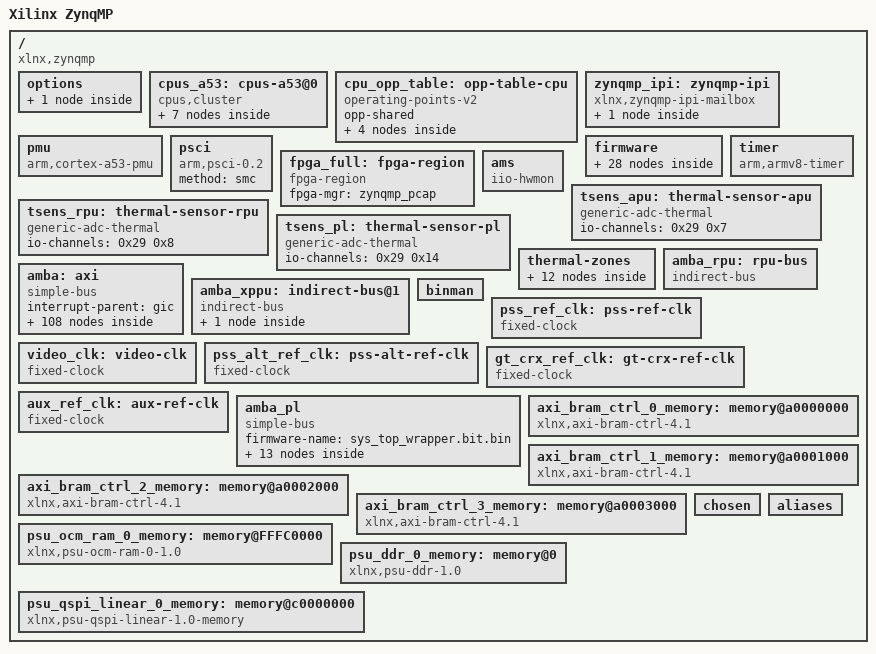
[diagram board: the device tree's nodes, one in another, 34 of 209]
/dts-v1/;
/ {
        compatible = "xlnx,zynqmp";
        #address-cells = <0x2>;
        #size-cells = <0x2>;
        model = "Xilinx ZynqMP";
        device_id = "xczu17eg";
        slrcount = <0x1>;
        family = "ZynqMP";
        speed_grade = "2";
        pruned-sdt = <0x1>;

        options {

                u-boot {
                        compatible = "u-boot,config";
                        bootscr-address = <0x0 0x20000000>;
                };
        };

        cpus_a53: cpus-a53@0 {
                #address-cells = <0x1>;
                #size-cells = <0x0>;
                compatible = "cpus,cluster";
                address-map = <0x0 0xf0000000 &amba 0x0 0xf0000000 0x0 0x10000000>,
                 <0x0 0x0 &zynqmp_reset 0x0 0x0 0x0 0x0>,
                 <0x0 0x0 &pinctrl0 0x0 0x0 0x0 0x0>,
                 <0x0 0xffa50800 &ams_ps 0x0 0xffa50800 0x0 0x400>,
                 <0x0 0xffa50c00 &ams_pl 0x0 0xffa50c00 0x0 0x400>,
                 <0x0 0xa0000000 &axi_bram_ctrl_0_memory 0x0 0xa0000000 0x0 0x1000>,
                 <0x0 0xa0000000 &axi_bram_ctrl_0 0x0 0xa0000000 0x0 0x1000>,
                 <0x0 0xa0001000 &axi_bram_ctrl_1_memory 0x0 0xa0001000 0x0 0x1000>,
                 <0x0 0xa0001000 &axi_bram_ctrl_1 0x0 0xa0001000 0x0 0x1000>,
                 <0x0 0xa0002000 &axi_bram_ctrl_2_memory 0x0 0xa0002000 0x0 0x1000>,
                 <0x0 0xa0002000 &axi_bram_ctrl_2 0x0 0xa0002000 0x0 0x1000>,
                 <0x0 0xa0003000 &axi_bram_ctrl_3_memory 0x0 0xa0003000 0x0 0x1000>,
                 <0x0 0xa0003000 &axi_bram_ctrl_3 0x0 0xa0003000 0x0 0x1000>,
                 <0x0 0xfffc0000 &psu_ocm_ram_0_memory 0x0 0xfffc0000 0x0 0x40000>,
                 <0x0 0xff300000 &ipi0 0x0 0xff300000 0x0 0x10000>,
                 <0x0 0x0 &psu_ddr_0_memory 0x0 0x0 0x0 0x7ff00000>,
                 <0x0 0xa0010000 &t4nfc_hlper_0 0x0 0xa0010000 0x0 0x10000>,
                 <0x0 0xa0020000 &t4nfc_hlper_1 0x0 0xa0020000 0x0 0x10000>,
                 <0x0 0xa0030000 &t4nfc_hlper_2 0x0 0xa0030000 0x0 0x10000>,
                 <0x0 0xa0040000 &t4nfc_hlper_3 0x0 0xa0040000 0x0 0x10000>,
                 <0x0 0xb0000000 &iodelay_if_0 0x0 0xb0000000 0x0 0x10000>,
                 <0x0 0xb0010000 &iodelay_if_0_dqs 0x0 0xb0010000 0x0 0x10000>,
                 <0x0 0xb0020000 &nvme_ctrl_0 0x0 0xb0020000 0x0 0x20000>,
                 <0x0 0xf9010000 &gic 0x0 0xf9010000 0x0 0x70000>,
                 <0x0 0xffa80000 &lpd_dma_chan1 0x0 0xffa80000 0x0 0x10000>,
                 <0x0 0xffa90000 &lpd_dma_chan2 0x0 0xffa90000 0x0 0x10000>,
                 <0x0 0xffaa0000 &lpd_dma_chan3 0x0 0xffaa0000 0x0 0x10000>,
                 <0x0 0xffab0000 &lpd_dma_chan4 0x0 0xffab0000 0x0 0x10000>,
                 <0x0 0xffac0000 &lpd_dma_chan5 0x0 0xffac0000 0x0 0x10000>,
                 <0x0 0xffad0000 &lpd_dma_chan6 0x0 0xffad0000 0x0 0x10000>,
                 <0x0 0xffae0000 &lpd_dma_chan7 0x0 0xffae0000 0x0 0x10000>,
                 <0x0 0xffaf0000 &lpd_dma_chan8 0x0 0xffaf0000 0x0 0x10000>,
                 <0x0 0xfd360000 &psu_afi_0 0x0 0xfd360000 0x0 0x10000>,
                 <0x0 0xfd370000 &psu_afi_1 0x0 0xfd370000 0x0 0x10000>,
                 <0x0 0xfd380000 &psu_afi_2 0x0 0xfd380000 0x0 0x10000>,
                 <0x0 0xfd390000 &psu_afi_3 0x0 0xfd390000 0x0 0x10000>,
                 <0x0 0xfd3a0000 &psu_afi_4 0x0 0xfd3a0000 0x0 0x10000>,
                 <0x0 0xfd3b0000 &psu_afi_5 0x0 0xfd3b0000 0x0 0x10000>,
                 <0x0 0xff9b0000 &psu_afi_6 0x0 0xff9b0000 0x0 0x10000>,
                 <0x0 0xffa50000 &xilinx_ams 0x0 0xffa50000 0x0 0x10000>,
                 <0x0 0xfd0b0000 &perf_monitor_ddr 0x0 0xfd0b0000 0x0 0x10000>,
                 <0x0 0xffa00000 &perf_monitor_ocm 0x0 0xffa00000 0x0 0x10000>,
                 <0x0 0xffa10000 &perf_monitor_lpd 0x0 0xffa10000 0x0 0x10000>,
                 <0x0 0xfd490000 &perf_monitor_cci 0x0 0xfd490000 0x0 0x10000>,
                 <0x0 0xfd5c0000 &psu_apu 0x0 0xfd5c0000 0x0 0x10000>,
                 <0x0 0xfd6e0000 &psu_cci_gpv 0x0 0xfd6e0000 0x0 0x10000>,
                 <0x0 0xfd5e0000 &psu_cci_reg 0x0 0xfd5e0000 0x0 0x10000>,
                 <0x0 0xfe800000 &coresight_0 0x0 0xfe800000 0x0 0x800000>,
                 <0x0 0xfd1a0000 &psu_crf_apb 0x0 0xfd1a0000 0x0 0x140000>,
                 <0x0 0xff5e0000 &psu_crl_apb 0x0 0xff5e0000 0x0 0x280000>,
                 <0x0 0xffca0000 &psu_csu_0 0x0 0xffca0000 0x0 0x10000>,
                 <0x0 0xffc80000 &csudma_0 0x0 0xffc80000 0x0 0x20000>,
                 <0x0 0xff380000 &psu_ctrl_ipi 0x0 0xff380000 0x0 0x80000>,
                 <0x0 0xfd080000 &psu_ddr_phy 0x0 0xfd080000 0x0 0x10000>,
                 <0x0 0xfd090000 &psu_ddr_qos_ctrl 0x0 0xfd090000 0x0 0x10000>,
                 <0x0 0xfd000000 &psu_ddr_xmpu0_cfg 0x0 0xfd000000 0x0 0x10000>,
                 <0x0 0xfd010000 &psu_ddr_xmpu1_cfg 0x0 0xfd010000 0x0 0x10000>,
                 <0x0 0xfd020000 &psu_ddr_xmpu2_cfg 0x0 0xfd020000 0x0 0x10000>,
                 <0x0 0xfd030000 &psu_ddr_xmpu3_cfg 0x0 0xfd030000 0x0 0x10000>,
                 <0x0 0xfd040000 &psu_ddr_xmpu4_cfg 0x0 0xfd040000 0x0 0x10000>,
                 <0x0 0xfd050000 &psu_ddr_xmpu5_cfg 0x0 0xfd050000 0x0 0x10000>,
                 <0x0 0xfd070000 &mc 0x0 0xfd070000 0x0 0x1000>,
                 <0x0 0xffcc0000 &psu_efuse 0x0 0xffcc0000 0x0 0x10000>,
                 <0x0 0xff0e0000 &gem3 0x0 0xff0e0000 0x0 0x10000>,
                 <0x0 0xfd700000 &psu_fpd_gpv 0x0 0xfd700000 0x0 0x100000>,
                 <0x0 0xfd610000 &psu_fpd_slcr 0x0 0xfd610000 0x0 0x80000>,
                 <0x0 0xfd690000 &psu_fpd_slcr_secure 0x0 0xfd690000 0x0 0x40000>,
                 <0x0 0xfd5d0000 &psu_fpd_xmpu_cfg 0x0 0xfd5d0000 0x0 0x10000>,
                 <0x0 0xfd4f0000 &psu_fpd_xmpu_sink 0x0 0xfd4f0000 0x0 0x10000>,
                 <0x0 0xfd500000 &fpd_dma_chan1 0x0 0xfd500000 0x0 0x10000>,
                 <0x0 0xfd510000 &fpd_dma_chan2 0x0 0xfd510000 0x0 0x10000>,
                 <0x0 0xfd520000 &fpd_dma_chan3 0x0 0xfd520000 0x0 0x10000>,
                 <0x0 0xfd530000 &fpd_dma_chan4 0x0 0xfd530000 0x0 0x10000>,
                 <0x0 0xfd540000 &fpd_dma_chan5 0x0 0xfd540000 0x0 0x10000>,
                 <0x0 0xfd550000 &fpd_dma_chan6 0x0 0xfd550000 0x0 0x10000>,
                 <0x0 0xfd560000 &fpd_dma_chan7 0x0 0xfd560000 0x0 0x10000>,
                 <0x0 0xfd570000 &fpd_dma_chan8 0x0 0xfd570000 0x0 0x10000>,
                 <0x0 0xff0a0000 &gpio 0x0 0xff0a0000 0x0 0x10000>,
                 <0x0 0xfd4b0000 &gpu 0x0 0xfd4b0000 0x0 0x10000>,
                 <0x0 0xff020000 &i2c0 0x0 0xff020000 0x0 0x10000>,
                 <0x0 0xff030000 &i2c1 0x0 0xff030000 0x0 0x10000>,
                 <0x0 0xff250000 &psu_iou_scntr 0x0 0xff250000 0x0 0x10000>,
                 <0x0 0xff260000 &psu_iou_scntrs 0x0 0xff260000 0x0 0x10000>,
                 <0x0 0xff240000 &psu_iousecure_slcr 0x0 0xff240000 0x0 0x10000>,
                 <0x0 0xff180000 &psu_iouslcr_0 0x0 0xff180000 0x0 0xc0000>,
                 <0x0 0xff410000 &psu_lpd_slcr 0x0 0xff410000 0x0 0xa0000>,
                 <0x0 0xff4b0000 &psu_lpd_slcr_secure 0x0 0xff4b0000 0x0 0x30000>,
                 <0x0 0xff980000 &lpd_xppu 0x0 0xff980000 0x0 0x10000>,
                 <0x0 0xff9c0000 &psu_lpd_xppu_sink 0x0 0xff9c0000 0x0 0x10000>,
                 <0x0 0xffcf0000 &psu_mbistjtag 0x0 0xffcf0000 0x0 0x10000>,
                 <0x0 0xff990000 &psu_message_buffers 0x0 0xff990000 0x0 0x10000>,
                 <0x0 0xff960000 &ocm 0x0 0xff960000 0x0 0x10000>,
                 <0x0 0xffa70000 &psu_ocm_xmpu_cfg 0x0 0xffa70000 0x0 0x10000>,
                 <0x0 0xffd80000 &psu_pmu_global_0 0x0 0xffd80000 0x0 0x40000>,
                 <0x0 0xff0f0000 &qspi 0x0 0xff0f0000 0x0 0x10000>,
                 <0x0 0xc0000000 &psu_qspi_linear_0_memory 0x0 0xc0000000 0x0 0x20000000>,
                 <0x0 0xffe00000 &psu_r5_0_atcm_global 0x0 0xffe00000 0x0 0x10000>,
                 <0x0 0xffe20000 &psu_r5_0_btcm_global 0x0 0xffe20000 0x0 0x10000>,
                 <0x0 0xffe90000 &psu_r5_1_atcm_global 0x0 0xffe90000 0x0 0x10000>,
                 <0x0 0xffeb0000 &psu_r5_1_btcm_global 0x0 0xffeb0000 0x0 0x10000>,
                 <0x0 0xffe00000 &psu_r5_tcm_ram_global 0x0 0xffe00000 0x0 0x40000>,
                 <0x0 0xff9a0000 &psu_rpu 0x0 0xff9a0000 0x0 0x10000>,
                 <0x0 0xffce0000 &psu_rsa 0x0 0xffce0000 0x0 0x10000>,
                 <0x0 0xffa60000 &rtc 0x0 0xffa60000 0x0 0x10000>,
                 <0x0 0xff170000 &sdhci1 0x0 0xff170000 0x0 0x10000>,
                 <0x0 0xfd400000 &psgtr 0x0 0xfd400000 0x0 0x80000>,
                 <0x0 0xfd3d0000 &psu_siou 0x0 0xfd3d0000 0x0 0x10000>,
                 <0x0 0xfd800000 &smmu 0x0 0xfd800000 0x0 0x800000>,
                 <0x0 0xfd5f0000 &psu_smmu_reg 0x0 0xfd5f0000 0x0 0x10000>,
                 <0x0 0xff000000 &uart0 0x0 0xff000000 0x0 0x10000>,
                 <0x0 0xff010000 &uart1 0x0 0xff010000 0x0 0x10000>;
                #ranges-address-cells = <0x2>;
                #ranges-size-cells = <0x2>;
                phandle = <0x9d>;

                psu_cortexa53_0: cpu@0 {
                        #cooling-cells = <0x2>;
                        compatible = "arm,cortex-a53";
                        device_type = "cpu";
                        enable-method = "psci";
                        operating-points-v2 = <&cpu_opp_table>;
                        reg = <0x0>;
                        cpu-idle-states = <&CPU_SLEEP_0>;
                        next-level-cache = <&L2>;
                        clocks = <&zynqmp_clk 0xa>;
                        xlnx,psu-ep = <0x1>;
                        xlnx,pss-video-ref-clk-freq = <0x1fc9f08>;
                        xlnx,ip-name = "psu_cortexa53";
                        xlnx,cpu-1x-clk-freq-hz = <0x0>;
                        xlnx,psu-silicon-version = <0x3>;
                        cpu-frequency = <0x4f78d984>;
                        xlnx,cpu-clk-freq-hz = <0x4f78d984>;
                        xlnx,pss-gt-ref-clk-freq = <0x1fc9f08>;
                        xlnx,pss-ref-clk-freq = <0x1fc9f08>;
                        bus-handle = <0x1>;
                        xlnx,pss-aux-ref-clk-freq = <0x1fc9f08>;
                        xlnx,psu-device = "PS8a";
                        xlnx,timestamp-clk-freq = <0x1fc9f08>;
                        stamp-frequency = <0x1fc9f08>;
                        xlnx,pss-alt-ref-clk-freq = <0x1fc9f08>;
                        phandle = <0x88>;
                };

                psu_cortexa53_1: cpu@1 {
                        #cooling-cells = <0x2>;
                        compatible = "arm,cortex-a53";
                        device_type = "cpu";
                        enable-method = "psci";
                        reg = <0x1>;
                        operating-points-v2 = <&cpu_opp_table>;
                        cpu-idle-states = <&CPU_SLEEP_0>;
                        next-level-cache = <&L2>;
                        xlnx,timestamp-clk-freq = <0x1fc9f08>;
                        xlnx,psu-ep = <0x1>;
                        xlnx,pss-ref-clk-freq = <0x1fc9f08>;
                        stamp-frequency = <0x1fc9f08>;
                        xlnx,cpu-1x-clk-freq-hz = <0x0>;
                        xlnx,ip-name = "psu_cortexa53";
                        xlnx,psu-silicon-version = <0x3>;
                        xlnx,psu-device = "PS8a";
                        xlnx,cpu-clk-freq-hz = <0x4f78d984>;
                        bus-handle = <0x1>;
                        cpu-frequency = <0x4f78d984>;
                        phandle = <0x89>;
                };

                psu_cortexa53_2: cpu@2 {
                        #cooling-cells = <0x2>;
                        compatible = "arm,cortex-a53";
                        device_type = "cpu";
                        enable-method = "psci";
                        reg = <0x2>;
                        operating-points-v2 = <&cpu_opp_table>;
                        cpu-idle-states = <&CPU_SLEEP_0>;
                        next-level-cache = <&L2>;
                        xlnx,timestamp-clk-freq = <0x1fc9f08>;
                        xlnx,psu-ep = <0x1>;
                        xlnx,pss-ref-clk-freq = <0x1fc9f08>;
                        stamp-frequency = <0x1fc9f08>;
                        xlnx,cpu-1x-clk-freq-hz = <0x0>;
                        xlnx,ip-name = "psu_cortexa53";
                        xlnx,psu-silicon-version = <0x3>;
                        xlnx,psu-device = "PS8a";
                        xlnx,cpu-clk-freq-hz = <0x4f78d984>;
                        bus-handle = <0x1>;
                        cpu-frequency = <0x4f78d984>;
                        phandle = <0x8a>;
                };

                psu_cortexa53_3: cpu@3 {
                        #cooling-cells = <0x2>;
                        compatible = "arm,cortex-a53";
                        device_type = "cpu";
                        enable-method = "psci";
                        reg = <0x3>;
                        operating-points-v2 = <&cpu_opp_table>;
                        cpu-idle-states = <&CPU_SLEEP_0>;
                        next-level-cache = <&L2>;
                        xlnx,timestamp-clk-freq = <0x1fc9f08>;
                        xlnx,psu-ep = <0x1>;
                        xlnx,pss-ref-clk-freq = <0x1fc9f08>;
                        stamp-frequency = <0x1fc9f08>;
                        xlnx,cpu-1x-clk-freq-hz = <0x0>;
                        xlnx,ip-name = "psu_cortexa53";
                        xlnx,psu-silicon-version = <0x3>;
                        xlnx,psu-device = "PS8a";
                        xlnx,cpu-clk-freq-hz = <0x4f78d984>;
                        bus-handle = <0x1>;
                        cpu-frequency = <0x4f78d984>;
                        phandle = <0x8b>;
                };

                L2: l2-cache {
                        compatible = "cache";
                        cache-level = <0x2>;
                        cache-unified;
                        phandle = <0x73>;
                };

                idle-states {
                        entry-method = "psci";

                        CPU_SLEEP_0: cpu-sleep-0 {
                                compatible = "arm,idle-state";
                                arm,psci-suspend-param = <0x40000000>;
                                local-timer-stop;
                                entry-latency-us = <0x12c>;
                                exit-latency-us = <0x258>;
                                min-residency-us = <0x2710>;
                                phandle = <0x72>;
                        };
                };
        };

        cpu_opp_table: opp-table-cpu {
                compatible = "operating-points-v2";
                opp-shared;
                phandle = <0x71>;

                opp-1334000000 {
                        opp-hz = <0x0 0x4f833980>;
                        clock-latency-ns = <0x7a120>;
                        opp-microvolt = <0xf4240>;
                };

                opp-667000000 {
                        opp-hz = <0x0 0x27c19cc0>;
                        clock-latency-ns = <0x7a120>;
                        opp-microvolt = <0xf4240>;
                };

                opp-444666667 {
                        opp-hz = <0x0 0x1a81132b>;
                        clock-latency-ns = <0x7a120>;
                        opp-microvolt = <0xf4240>;
                };

                opp-333500000 {
                        opp-hz = <0x0 0x13e0ce60>;
                        clock-latency-ns = <0x7a120>;
                        opp-microvolt = <0xf4240>;
                };
        };

        zynqmp_ipi: zynqmp-ipi {
                bootph-all;
                compatible = "xlnx,zynqmp-ipi-mailbox";
                interrupt-parent = <&gic>;
                interrupts = <0x0 0x23 0x4>;
                xlnx,ipi-id = <0x0>;
                #address-cells = <0x2>;
                #size-cells = <0x2>;
                ranges;
                phandle = <0xa4>;

                ipi_mailbox_pmu1: mailbox@ff9905c0 {
                        bootph-all;
                        compatible = "xlnx,zynqmp-ipi-dest-mailbox";
                        reg = <0x0 0xff9905c0 0x0 0x20 0x0 0xff9905e0 0x0 0x20 0x0 0xff990e80 0x0 0x20 0x0 0xff990ea0 0x0 0x20>;
                        reg-names = "local_request_region", "local_response_region", "remote_request_region", "remote_response_region";
                        #mbox-cells = <0x1>;
                        xlnx,ipi-id = <0x4>;
                        phandle = <0x8c>;
                };
        };

        pmu {
                compatible = "arm,cortex-a53-pmu";
                interrupt-parent = <&gic>;
                interrupts = <0x0 0x8f 0x4 0x0 0x90 0x4 0x0 0x91 0x4 0x0 0x92 0x4>;
                interrupt-affinity = <&psu_cortexa53_0>,
                 <&psu_cortexa53_1>,
                 <&psu_cortexa53_2>,
                 <&psu_cortexa53_3>;
        };

        psci {
                compatible = "arm,psci-0.2";
                method = "smc";
        };

        firmware {

                zynqmp_firmware: zynqmp-firmware {
                        compatible = "xlnx,zynqmp-firmware";
                        #power-domain-cells = <0x1>;
                        method = "smc";
                        bootph-all;
                        phandle = <0x7c>;

                        zynqmp_power: power-management {
                                bootph-all;
                                compatible = "xlnx,zynqmp-power";
                                interrupt-parent = <&gic>;
                                interrupts = <0x0 0x23 0x4>;
                                mboxes = <0x8c 0x0 0x8c 0x1>;
                                mbox-names = "tx", "rx";
                                phandle = <0xa6>;
                        };

                        soc-nvmem {
                                compatible = "xlnx,zynqmp-nvmem-fw";

                                nvmem-layout {
                                        compatible = "fixed-layout";
                                        #address-cells = <0x1>;
                                        #size-cells = <0x1>;

                                        soc_revision: soc-revision@0 {
                                                reg = <0x0 0x4>;
                                                phandle = <0xa7>;
                                        };

                                        efuse_dna: efuse-dna@c {
                                                reg = <0xc 0xc>;
                                                phandle = <0xa8>;
                                        };

                                        efuse_usr0: efuse-usr0@20 {
                                                reg = <0x20 0x4>;
                                                phandle = <0xa9>;
                                        };

                                        efuse_usr1: efuse-usr1@24 {
                                                reg = <0x24 0x4>;
                                                phandle = <0xaa>;
                                        };

                                        efuse_usr2: efuse-usr2@28 {
                                                reg = <0x28 0x4>;
                                                phandle = <0xab>;
                                        };

                                        efuse_usr3: efuse-usr3@2c {
                                                reg = <0x2c 0x4>;
                                                phandle = <0xac>;
                                        };

                                        efuse_usr4: efuse-usr4@30 {
                                                reg = <0x30 0x4>;
                                                phandle = <0xad>;
                                        };

                                        efuse_usr5: efuse-usr5@34 {
                                                reg = <0x34 0x4>;
                                                phandle = <0xae>;
                                        };

                                        efuse_usr6: efuse-usr6@38 {
                                                reg = <0x38 0x4>;
                                                phandle = <0xaf>;
                                        };

                                        efuse_usr7: efuse-usr7@3c {
                                                reg = <0x3c 0x4>;
                                                phandle = <0xb0>;
                                        };

                                        efuse_miscusr: efuse-miscusr@40 {
                                                reg = <0x40 0x4>;
                                                phandle = <0xb1>;
                                        };

                                        efuse_chash: efuse-chash@50 {
                                                reg = <0x50 0x4>;
                                                phandle = <0xb2>;
                                        };

                                        efuse_pufmisc: efuse-pufmisc@54 {
                                                reg = <0x54 0x4>;
                                                phandle = <0xb3>;
                                        };

                                        efuse_sec: efuse-sec@58 {
                                                reg = <0x58 0x4>;
                                                phandle = <0xb4>;
                                        };

                                        efuse_spkid: efuse-spkid@5c {
                                                reg = <0x5c 0x4>;
                                                phandle = <0xb5>;
                                        };

                                        efuse_aeskey: efuse-aeskey@60 {
                                                reg = <0x60 0x20>;
                                                phandle = <0xb6>;
                                        };

                                        efuse_ppk0hash: efuse-ppk0hash@a0 {
                                                reg = <0xa0 0x30>;
                                                phandle = <0xb7>;
                                        };

                                        efuse_ppk1hash: efuse-ppk1hash@d0 {
                                                reg = <0xd0 0x30>;
                                                phandle = <0xb8>;
                                        };

                                        efuse_pufuser: efuse-pufuser@100 {
                                                reg = <0x100 0x7f>;
                                                phandle = <0xb9>;
                                        };
                                };
                        };

                        zynqmp_pcap: pcap {
                                compatible = "xlnx,zynqmp-pcap-fpga";
                                phandle = <0x92>;
                        };

                        zynqmp_reset: reset-controller {
                                compatible = "xlnx,zynqmp-reset";
                                #reset-cells = <0x1>;
                                status = "okay";
                                phandle = <0x3>;
                        };

                        pinctrl0: pinctrl {
                                compatible = "xlnx,zynqmp-pinctrl";
                                status = "okay";
                                phandle = <0x4>;
                        };

                        modepin_gpio: gpio {
                                compatible = "xlnx,zynqmp-gpio-modepin";
                                gpio-controller;
                                #gpio-cells = <0x2>;
                                phandle = <0x99>;
                        };

                        zynqmp_clk: clock-controller {
                                bootph-all;
                                #clock-cells = <0x1>;
                                compatible = "xlnx,zynqmp-clk";
                                clocks = <&pss_ref_clk>,
                                 <&video_clk>,
                                 <&pss_alt_ref_clk>,
                                 <&aux_ref_clk>,
                                 <&gt_crx_ref_clk>;
                                clock-names = "pss_ref_clk", "video_clk", "pss_alt_ref_clk", "aux_ref_clk", "gt_crx_ref_clk";
                                phandle = <0x74>;
                        };
                };
        };

        timer {
                compatible = "arm,armv8-timer";
                interrupt-parent = <&gic>;
                interrupts = <0x1 0xd 0xf08 0x1 0xe 0xf08 0x1 0xb 0xf08 0x1 0xa 0xf08>;
        };

        fpga_full: fpga-region {
                compatible = "fpga-region";
                fpga-mgr = <&zynqmp_pcap>;
                #address-cells = <0x2>;
                #size-cells = <0x2>;
                ranges;
                phandle = <0xba>;
        };

        ams {
                compatible = "iio-hwmon";
                io-channels = <0x29 0x0 0x29 0x1 0x29 0x2 0x29 0x3 0x29 0x4 0x29 0x5 0x29 0x6 0x29 0x7 0x29 0x8 0x29 0x9 0x29 0xa 0x29 0xb 0x29 0xc 0x29 0xd 0x29 0xe 0x29 0xf 0x29 0x10 0x29 0x11 0x29 0x12 0x29 0x13 0x29 0x14 0x29 0x15 0x29 0x16 0x29 0x17 0x29 0x18 0x29 0x19 0x29 0x1a 0x29 0x1b 0x29 0x1c 0x29 0x1d>;
        };

        tsens_apu: thermal-sensor-apu {
                compatible = "generic-adc-thermal";
                #thermal-sensor-cells = <0x0>;
                io-channels = <0x29 0x7>;
                io-channel-names = "sensor-channel";
                phandle = <0x93>;
        };

        tsens_rpu: thermal-sensor-rpu {
                compatible = "generic-adc-thermal";
                #thermal-sensor-cells = <0x0>;
                io-channels = <0x29 0x8>;
                io-channel-names = "sensor-channel";
                phandle = <0x95>;
        };

        tsens_pl: thermal-sensor-pl {
                compatible = "generic-adc-thermal";
                #thermal-sensor-cells = <0x0>;
                io-channels = <0x29 0x14>;
                io-channel-names = "sensor-channel";
                phandle = <0x96>;
        };

        thermal-zones {

                apu-thermal {
                        polling-delay-passive = <0x3e8>;
                        polling-delay = <0x1388>;
                        thermal-sensors = <0x93>;

                        trips {

                                apu_passive: passive {
                                        temperature = <0x16b48>;
                                        hysteresis = <0xdac>;
                                        type = "passive";
                                        phandle = <0x94>;
                                };

                                apu_critical: critical {
                                        temperature = <0x178f4>;
                                        hysteresis = <0xdac>;
                                        type = "critical";
                                        phandle = <0xbb>;
                                };
                        };

                        cooling-maps {

                                map {
                                        trip = <0x94>;
                                        cooling-device = <0x88 0xffffffff 0xffffffff 0x89 0xffffffff 0xffffffff 0x8a 0xffffffff 0xffffffff 0x8b 0xffffffff 0xffffffff>;
                                };
                        };
                };

                rpu-thermal {
                        polling-delay = <0x2710>;
                        thermal-sensors = <0x95>;

                        trips {

                                critical {
                                        temperature = <0x178f4>;
                                        hysteresis = <0xdac>;
                                        type = "critical";
                                };
                        };
                };

                pl-thermal {
                        polling-delay = <0x2710>;
                        thermal-sensors = <0x96>;

                        trips {

                                critical {
                                        temperature = <0x178f4>;
                                        hysteresis = <0xdac>;
                                        type = "critical";
                                };
                        };
                };
        };

        amba_rpu: rpu-bus {
                compatible = "indirect-bus";
                #address-cells = <0x2>;
                #size-cells = <0x1>;
                phandle = <0x75>;
        };

        amba: axi {
                compatible = "simple-bus";
                bootph-all;
                #address-cells = <0x2>;
                #size-cells = <0x2>;
                ranges;
                interrupt-parent = <&gic>;
                phandle = <0x1>;

                psu_cortexa53_0_debug: debug@fec10000 {
                        compatible = "arm,coresight-cpu-debug", "arm,primecell";
                        reg = <0x0 0xfec10000 0x0 0x1000>;
                        clock-names = "apb_pclk";
                        cpu = <0x88>;
                        clocks = <&zynqmp_clk 0xc>;
                        phandle = <0xbf>;
                };

                psu_cortexa53_1_debug: debug@fed10000 {
                        compatible = "arm,coresight-cpu-debug", "arm,primecell";
                        reg = <0x0 0xfed10000 0x0 0x1000>;
                        clock-names = "apb_pclk";
                        cpu = <0x89>;
                        clocks = <&zynqmp_clk 0xc>;
                        phandle = <0xc0>;
                };

                psu_cortexa53_2_debug: debug@fee10000 {
                        compatible = "arm,coresight-cpu-debug", "arm,primecell";
                        reg = <0x0 0xfee10000 0x0 0x1000>;
                        clock-names = "apb_pclk";
                        cpu = <0x8a>;
                        clocks = <&zynqmp_clk 0xc>;
                        phandle = <0xc1>;
                };

                psu_cortexa53_3_debug: debug@fef10000 {
                        compatible = "arm,coresight-cpu-debug", "arm,primecell";
                        reg = <0x0 0xfef10000 0x0 0x1000>;
                        clock-names = "apb_pclk";
                        cpu = <0x8b>;
                        clocks = <&zynqmp_clk 0xc>;
                        phandle = <0xc2>;
                };

                fpd_dma_chan1: dma-controller@fd500000 {
                        status = "okay";
                        compatible = "xlnx,zynqmp-dma-1.0";
                        reg = <0x0 0xfd500000 0x0 0x1000>;
                        interrupt-parent = <&gic>;
                        interrupts = <0x0 0x7c 0x4>;
                        clock-names = "clk_main", "clk_apb";
                        #dma-cells = <0x1>;
                        xlnx,bus-width = <0x80>;
                        power-domains = <&zynqmp_firmware 0x2a>;
                        clocks = <&zynqmp_clk 0x13>,
                         <&zynqmp_clk 0x1f>;
                        xlnx,ip-name = "psu_gdma";
                        xlnx,dma-mode = <0x0>;
                        xlnx,dma-type = <0x0>;
                        xlnx,name = "psu_gdma_0";
                        phandle = <0x47>;
                };

                fpd_dma_chan2: dma-controller@fd510000 {
                        status = "okay";
                        compatible = "xlnx,zynqmp-dma-1.0";
                        reg = <0x0 0xfd510000 0x0 0x1000>;
                        interrupt-parent = <&gic>;
                        interrupts = <0x0 0x7d 0x4>;
                        clock-names = "clk_main", "clk_apb";
                        #dma-cells = <0x1>;
                        xlnx,bus-width = <0x80>;
                        power-domains = <&zynqmp_firmware 0x2a>;
                        clocks = <&zynqmp_clk 0x13>,
                         <&zynqmp_clk 0x1f>;
                        xlnx,ip-name = "psu_gdma";
                        xlnx,dma-mode = <0x0>;
                        xlnx,dma-type = <0x0>;
                        xlnx,name = "psu_gdma_1";
                        phandle = <0x48>;
                };

                fpd_dma_chan3: dma-controller@fd520000 {
                        status = "okay";
                        compatible = "xlnx,zynqmp-dma-1.0";
                        reg = <0x0 0xfd520000 0x0 0x1000>;
                        interrupt-parent = <&gic>;
                        interrupts = <0x0 0x7e 0x4>;
                        clock-names = "clk_main", "clk_apb";
                        #dma-cells = <0x1>;
                        xlnx,bus-width = <0x80>;
                        power-domains = <&zynqmp_firmware 0x2a>;
                        clocks = <&zynqmp_clk 0x13>,
                         <&zynqmp_clk 0x1f>;
                        xlnx,ip-name = "psu_gdma";
                        xlnx,dma-mode = <0x0>;
                        xlnx,dma-type = <0x0>;
                        xlnx,name = "psu_gdma_2";
                        phandle = <0x49>;
                };

                fpd_dma_chan4: dma-controller@fd530000 {
                        status = "okay";
                        compatible = "xlnx,zynqmp-dma-1.0";
                        reg = <0x0 0xfd530000 0x0 0x1000>;
                        interrupt-parent = <&gic>;
                        interrupts = <0x0 0x7f 0x4>;
                        clock-names = "clk_main", "clk_apb";
                        #dma-cells = <0x1>;
                        xlnx,bus-width = <0x80>;
                        power-domains = <&zynqmp_firmware 0x2a>;
                        clocks = <&zynqmp_clk 0x13>,
                         <&zynqmp_clk 0x1f>;
                        xlnx,ip-name = "psu_gdma";
                        xlnx,dma-mode = <0x0>;
                        xlnx,dma-type = <0x0>;
                        xlnx,name = "psu_gdma_3";
                        phandle = <0x4a>;
                };

                fpd_dma_chan5: dma-controller@fd540000 {
                        status = "okay";
                        compatible = "xlnx,zynqmp-dma-1.0";
                        reg = <0x0 0xfd540000 0x0 0x1000>;
                        interrupt-parent = <&gic>;
                        interrupts = <0x0 0x80 0x4>;
                        clock-names = "clk_main", "clk_apb";
                        #dma-cells = <0x1>;
                        xlnx,bus-width = <0x80>;
                        power-domains = <&zynqmp_firmware 0x2a>;
                        clocks = <&zynqmp_clk 0x13>,
                         <&zynqmp_clk 0x1f>;
                        xlnx,ip-name = "psu_gdma";
                        xlnx,dma-mode = <0x0>;
                        xlnx,dma-type = <0x0>;
                        xlnx,name = "psu_gdma_4";
                        phandle = <0x4b>;
                };

                fpd_dma_chan6: dma-controller@fd550000 {
                        status = "okay";
                        compatible = "xlnx,zynqmp-dma-1.0";
                        reg = <0x0 0xfd550000 0x0 0x1000>;
                        interrupt-parent = <&gic>;
                        interrupts = <0x0 0x81 0x4>;
                        clock-names = "clk_main", "clk_apb";
                        #dma-cells = <0x1>;
                        xlnx,bus-width = <0x80>;
                        power-domains = <&zynqmp_firmware 0x2a>;
                        clocks = <&zynqmp_clk 0x13>,
                         <&zynqmp_clk 0x1f>;
                        xlnx,ip-name = "psu_gdma";
                        xlnx,dma-mode = <0x0>;
                        xlnx,dma-type = <0x0>;
                        xlnx,name = "psu_gdma_5";
                        phandle = <0x4c>;
                };

                fpd_dma_chan7: dma-controller@fd560000 {
                        status = "okay";
                        compatible = "xlnx,zynqmp-dma-1.0";
                        reg = <0x0 0xfd560000 0x0 0x1000>;
                        interrupt-parent = <&gic>;
                        interrupts = <0x0 0x82 0x4>;
                        clock-names = "clk_main", "clk_apb";
                        #dma-cells = <0x1>;
                        xlnx,bus-width = <0x80>;
                        power-domains = <&zynqmp_firmware 0x2a>;
                        clocks = <&zynqmp_clk 0x13>,
                         <&zynqmp_clk 0x1f>;
                        xlnx,ip-name = "psu_gdma";
                        xlnx,dma-mode = <0x0>;
                        xlnx,dma-type = <0x0>;
                        xlnx,name = "psu_gdma_6";
                        phandle = <0x4d>;
                };

                fpd_dma_chan8: dma-controller@fd570000 {
                        status = "okay";
                        compatible = "xlnx,zynqmp-dma-1.0";
                        reg = <0x0 0xfd570000 0x0 0x1000>;
                        interrupt-parent = <&gic>;
                        interrupts = <0x0 0x83 0x4>;
                        clock-names = "clk_main", "clk_apb";
                        #dma-cells = <0x1>;
                        xlnx,bus-width = <0x80>;
                        power-domains = <&zynqmp_firmware 0x2a>;
                        clocks = <&zynqmp_clk 0x13>,
                         <&zynqmp_clk 0x1f>;
                        xlnx,ip-name = "psu_gdma";
                        xlnx,dma-mode = <0x0>;
                        xlnx,dma-type = <0x0>;
                        xlnx,name = "psu_gdma_7";
                        phandle = <0x4e>;
                };

                gpu: gpu@fd4b0000 {
                        status = "okay";
                        compatible = "xlnx,zynqmp-mali", "arm,mali-400";
                        reg = <0x0 0xfd4b0000 0x0 0x10000>;
                        interrupt-parent = <&gic>;
                        interrupts = <0x0 0x84 0x4 0x0 0x84 0x4 0x0 0x84 0x4 0x0 0x84 0x4 0x0 0x84 0x4 0x0 0x84 0x4>;
                        interrupt-names = "gp", "gpmmu", "pp0", "ppmmu0", "pp1", "ppmmu1";
                        clock-names = "bus", "core";
                        power-domains = <&zynqmp_firmware 0x3a>;
                        clocks = <&zynqmp_clk 0x18>,
                         <&zynqmp_clk 0x19>;
                        xlnx,ip-name = "psu_gpu";
                        xlnx,tz-nonsecure = <0x1>;
                        xlnx,name = "psu_gpu";
                        phandle = <0x50>;
                };

                lpd_dma_chan1: dma-controller@ffa80000 {
                        status = "okay";
                        compatible = "xlnx,zynqmp-dma-1.0";
                        reg = <0x0 0xffa80000 0x0 0x1000>;
                        interrupt-parent = <&gic>;
                        interrupts = <0x0 0x4d 0x4>;
                        clock-names = "clk_main", "clk_apb";
                        #dma-cells = <0x1>;
                        xlnx,bus-width = <0x40>;
                        power-domains = <&zynqmp_firmware 0x2b>;
                        clocks = <&zynqmp_clk 0x44>,
                         <&zynqmp_clk 0x1f>;
                        xlnx,is-cache-coherent = <0x0>;
                        xlnx,ip-name = "psu_adma";
                        xlnx,dma-mode = <0x1>;
                        xlnx,dma-type = <0x1>;
                        xlnx,name = "psu_adma_0";
                        phandle = <0x1a>;
                };

                lpd_dma_chan2: dma-controller@ffa90000 {
                        status = "okay";
                        compatible = "xlnx,zynqmp-dma-1.0";
                        reg = <0x0 0xffa90000 0x0 0x1000>;
                        interrupt-parent = <&gic>;
                        interrupts = <0x0 0x4e 0x4>;
                        clock-names = "clk_main", "clk_apb";
                        #dma-cells = <0x1>;
                        xlnx,bus-width = <0x40>;
                        power-domains = <&zynqmp_firmware 0x2b>;
                        clocks = <&zynqmp_clk 0x44>,
                         <&zynqmp_clk 0x1f>;
                        xlnx,is-cache-coherent = <0x0>;
                        xlnx,ip-name = "psu_adma";
                        xlnx,dma-mode = <0x1>;
                        xlnx,dma-type = <0x1>;
                        xlnx,name = "psu_adma_1";
                        phandle = <0x1b>;
                };

                lpd_dma_chan3: dma-controller@ffaa0000 {
                        status = "okay";
                        compatible = "xlnx,zynqmp-dma-1.0";
                        reg = <0x0 0xffaa0000 0x0 0x1000>;
                        interrupt-parent = <&gic>;
                        interrupts = <0x0 0x4f 0x4>;
                        clock-names = "clk_main", "clk_apb";
                        #dma-cells = <0x1>;
                        xlnx,bus-width = <0x40>;
                        power-domains = <&zynqmp_firmware 0x2b>;
                        clocks = <&zynqmp_clk 0x44>,
                         <&zynqmp_clk 0x1f>;
                        xlnx,is-cache-coherent = <0x0>;
                        xlnx,ip-name = "psu_adma";
                        xlnx,dma-mode = <0x1>;
                        xlnx,dma-type = <0x1>;
                        xlnx,name = "psu_adma_2";
                        phandle = <0x1c>;
                };

                lpd_dma_chan4: dma-controller@ffab0000 {
                        status = "okay";
                        compatible = "xlnx,zynqmp-dma-1.0";
                        reg = <0x0 0xffab0000 0x0 0x1000>;
                        interrupt-parent = <&gic>;
                        interrupts = <0x0 0x50 0x4>;
                        clock-names = "clk_main", "clk_apb";
                        #dma-cells = <0x1>;
                        xlnx,bus-width = <0x40>;
                        power-domains = <&zynqmp_firmware 0x2b>;
                        clocks = <&zynqmp_clk 0x44>,
                         <&zynqmp_clk 0x1f>;
                        xlnx,is-cache-coherent = <0x0>;
                        xlnx,ip-name = "psu_adma";
                        xlnx,dma-mode = <0x1>;
                        xlnx,dma-type = <0x1>;
                        xlnx,name = "psu_adma_3";
                        phandle = <0x1d>;
                };

                lpd_dma_chan5: dma-controller@ffac0000 {
                        status = "okay";
                        compatible = "xlnx,zynqmp-dma-1.0";
                        reg = <0x0 0xffac0000 0x0 0x1000>;
                        interrupt-parent = <&gic>;
                        interrupts = <0x0 0x51 0x4>;
                        clock-names = "clk_main", "clk_apb";
                        #dma-cells = <0x1>;
                        xlnx,bus-width = <0x40>;
                        power-domains = <&zynqmp_firmware 0x2b>;
                        clocks = <&zynqmp_clk 0x44>,
                         <&zynqmp_clk 0x1f>;
                        xlnx,is-cache-coherent = <0x0>;
                        xlnx,ip-name = "psu_adma";
                        xlnx,dma-mode = <0x1>;
                        xlnx,dma-type = <0x1>;
                        xlnx,name = "psu_adma_4";
                        phandle = <0x1e>;
                };

                lpd_dma_chan6: dma-controller@ffad0000 {
                        status = "okay";
                        compatible = "xlnx,zynqmp-dma-1.0";
                        reg = <0x0 0xffad0000 0x0 0x1000>;
                        interrupt-parent = <&gic>;
                        interrupts = <0x0 0x52 0x4>;
                        clock-names = "clk_main", "clk_apb";
                        #dma-cells = <0x1>;
                        xlnx,bus-width = <0x40>;
                        power-domains = <&zynqmp_firmware 0x2b>;
                        clocks = <&zynqmp_clk 0x44>,
                         <&zynqmp_clk 0x1f>;
                        xlnx,is-cache-coherent = <0x0>;
                        xlnx,ip-name = "psu_adma";
                        xlnx,dma-mode = <0x1>;
                        xlnx,dma-type = <0x1>;
                        xlnx,name = "psu_adma_5";
                        phandle = <0x1f>;
                };

                lpd_dma_chan7: dma-controller@ffae0000 {
                        status = "okay";
                        compatible = "xlnx,zynqmp-dma-1.0";
                        reg = <0x0 0xffae0000 0x0 0x1000>;
                        interrupt-parent = <&gic>;
                        interrupts = <0x0 0x53 0x4>;
                        clock-names = "clk_main", "clk_apb";
                        #dma-cells = <0x1>;
                        xlnx,bus-width = <0x40>;
                        power-domains = <&zynqmp_firmware 0x2b>;
                        clocks = <&zynqmp_clk 0x44>,
                         <&zynqmp_clk 0x1f>;
                        xlnx,is-cache-coherent = <0x0>;
                        xlnx,ip-name = "psu_adma";
                        xlnx,dma-mode = <0x1>;
                        xlnx,dma-type = <0x1>;
                        xlnx,name = "psu_adma_6";
                        phandle = <0x20>;
                };

                lpd_dma_chan8: dma-controller@ffaf0000 {
                        status = "okay";
                        compatible = "xlnx,zynqmp-dma-1.0";
                        reg = <0x0 0xffaf0000 0x0 0x1000>;
                        interrupt-parent = <&gic>;
                        interrupts = <0x0 0x54 0x4>;
                        clock-names = "clk_main", "clk_apb";
                        #dma-cells = <0x1>;
                        xlnx,bus-width = <0x40>;
                        power-domains = <&zynqmp_firmware 0x2b>;
                        clocks = <&zynqmp_clk 0x44>,
                         <&zynqmp_clk 0x1f>;
                        xlnx,is-cache-coherent = <0x0>;
                        xlnx,ip-name = "psu_adma";
                        xlnx,dma-mode = <0x1>;
                        xlnx,dma-type = <0x1>;
                        xlnx,name = "psu_adma_7";
                        phandle = <0x21>;
                };

                mc: memory-controller@fd070000 {
                        compatible = "xlnx,zynqmp-ddrc-2.40a";
                        reg = <0x0 0xfd070000 0x0 0x30000>;
                        interrupt-parent = <&gic>;
                        interrupts = <0x0 0x70 0x4>;
                        xlnx,bank-addr-bits = <0x3>;
                        xlnx,has-ecc = <0x0>;
                        xlnx,ddr-freq = <0x2faee8c4>;
                        xlnx,row-addr-bits = <0x10>;
                        xlnx,ip-name = "psu_ddrc";
                        xlnx,ddrc-2nd-clock = <0x0>;
                        xlnx,brc-mapping = <0x0>;
                        xlnx,ddrc-address-copy = <0x1>;
                        xlnx,ddrc-data-mask-and-dbi = <0x7>;
                        xlnx,ddrc-memory-type = <0x5>;
                        xlnx,col-addr-bits = <0xa>;
                        xlnx,ddrc-max-operating-temparature = <0x0>;
                        status = "okay";
                        xlnx,ddrc-address-mirroring = <0x0>;
                        xlnx,ddrc-clk-freq-hz = <0x17d77462>;
                        xlnx,qos-enable = <0x0>;
                        xlnx,bg-addr-bits = <0x0>;
                        xlnx,ddrc-power-down-enable = <0x0>;
                        xlnx,video-buf-size = <0x0>;
                        xlnx,ddrc-memory-address-map = <0x0>;
                        xlnx,name = "psu_ddrc_0";
                        xlnx,dddrc-ecc = <0x0>;
                        xlnx,ddrc-clock-stop = <0x0>;
                        xlnx,ddrc-dynamic-ddr-config-enabled = <0x0>;
                        phandle = <0x3f>;
                };

                gem3: ethernet@ff0e0000 {
                        compatible = "xlnx,zynqmp-gem", "cdns,gem";
                        status = "okay";
                        interrupt-parent = <&gic>;
                        interrupts = <0x0 0x3f 0x4 0x0 0x3f 0x4>;
                        reg = <0x0 0xff0e0000 0x0 0x1000>;
                        clock-names = "pclk", "hclk", "tx_clk", "rx_clk", "tsu_clk";
                        power-domains = <&zynqmp_firmware 0x20>;
                        resets = <&zynqmp_reset 0x20>;
                        reset-names = "gem3_rst";
                        clocks = <&zynqmp_clk 0x1f>,
                         <&zynqmp_clk 0x6b>,
                         <&zynqmp_clk 0x30>,
                         <&zynqmp_clk 0x34>,
                         <&zynqmp_clk 0x2c>;
                        assigned-clocks = <&zynqmp_clk 0x2c>;
                        xlnx,is-cache-coherent = <0x0>;
                        xlnx,has-mdio = <0x2faf080>;
                        xlnx,gem-board-interface = "custom";
                        phy-mode = "rgmii-id";
                        xlnx,tz-nonsecure = <0x1>;
                        xlnx,enet-slcr-1000mbps-div0 = <0xc>;
                        xlnx,enet-slcr-10mbps-div0 = <0x3c>;
                        xlnx,enet-slcr-1000mbps-div1 = <0x1>;
                        xlnx,enet-slcr-10mbps-div1 = <0xa>;
                        xlnx,enet-tsu-clk-freq-hz = <0xee6a8ba>;
                        xlnx,ip-name = "psu_ethernet";
                        xlnx,eth-mode = <0x1>;
                        xlnx,enet-reset = <0x2faf080>;
                        xlnx,enet-clk-freq-hz = <0x773545d>;
                        xlnx,enet-slcr-100mbps-div0 = <0x3c>;
                        xlnx,ptp-enet-clock = <0x0>;
                        xlnx,enet-slcr-100mbps-div1 = <0x1>;
                        xlnx,name = "psu_ethernet_3";
                        phandle = <0x41>;
                };

                gpio: gpio@ff0a0000 {
                        compatible = "xlnx,zynqmp-gpio-1.0";
                        status = "okay";
                        #gpio-cells = <0x2>;
                        gpio-controller;
                        interrupt-parent = <&gic>;
                        interrupts = <0x0 0x10 0x4>;
                        interrupt-controller;
                        #interrupt-cells = <0x2>;
                        reg = <0x0 0xff0a0000 0x0 0x1000>;
                        power-domains = <&zynqmp_firmware 0x2e>;
                        clocks = <&zynqmp_clk 0x1f>;
                        xlnx,gpio-board-interface = "custom";
                        xlnx,mio-gpio-mask = <0x5600>;
                        gpio-mask-high = <0x0>;
                        xlnx,emio-gpio-width = <0x20>;
                        xlnx,ip-name = "psu_gpio";
                        gpio-mask-low = <0x5600>;
                        emio-gpio-width = <0x20>;
                        xlnx,name = "psu_gpio_0";
                        phandle = <0x4f>;
                };

                i2c0: i2c@ff020000 {
                        compatible = "cdns,i2c-r1p14";
                        status = "okay";
                        interrupt-parent = <&gic>;
                        interrupts = <0x0 0x11 0x4>;
                        clock-frequency = <0x61a80>;
                        reg = <0x0 0xff020000 0x0 0x1000>;
                        #address-cells = <0x1>;
                        #size-cells = <0x0>;
                        power-domains = <&zynqmp_firmware 0x25>;
                        clocks = <&zynqmp_clk 0x3d>;
                        xlnx,i2c-reset = <0x0>;
                        xlnx,has-interrupt = <0x2faf080>;
                        xlnx,clock-freq = <0x5f5dd19>;
                        xlnx,i2c-clk-freq-hz = <0x5f5dd19>;
                        xlnx,ip-name = "psu_i2c";
                        xlnx,iic-board-interface = "custom";
                        xlnx,name = "psu_i2c_0";
                        phandle = <0x51>;
                };

                i2c1: i2c@ff030000 {
                        compatible = "cdns,i2c-r1p14";
                        status = "okay";
                        interrupt-parent = <&gic>;
                        interrupts = <0x0 0x12 0x4>;
                        clock-frequency = <0x61a80>;
                        reg = <0x0 0xff030000 0x0 0x1000>;
                        #address-cells = <0x1>;
                        #size-cells = <0x0>;
                        power-domains = <&zynqmp_firmware 0x26>;
                        clocks = <&zynqmp_clk 0x3e>;
                        xlnx,i2c-reset = <0x0>;
                        xlnx,has-interrupt = <0x2faf080>;
                        xlnx,clock-freq = <0x5f5dd19>;
                        xlnx,i2c-clk-freq-hz = <0x5f5dd19>;
                        xlnx,ip-name = "psu_i2c";
                        xlnx,iic-board-interface = "custom";
                        xlnx,name = "psu_i2c_1";
                        phandle = <0x52>;
                };

                ocm: memory-controller@ff960000 {
                        compatible = "xlnx,zynqmp-ocmc-1.0";
                        reg = <0x0 0xff960000 0x0 0x1000>;
                        interrupt-parent = <&gic>;
                        interrupts = <0x0 0xa 0x4>;
                        status = "okay";
                        xlnx,ip-name = "psu_ocm";
                        xlnx,name = "psu_ocm";
                        phandle = <0x5d>;
                };

                perf_monitor_ocm: perf-monitor@ffa00000 {
                        compatible = "xlnx,axi-perf-monitor";
                        reg = <0x0 0xffa00000 0x0 0x10000>;
                        interrupts = <0x0 0x19 0x4>;
                        interrupt-parent = <&gic>;
                        xlnx,enable-profile = <0x0>;
                        xlnx,enable-trace = <0x0>;
                        xlnx,num-monitor-slots = <0x1>;
                        xlnx,enable-event-count = <0x1>;
                        xlnx,enable-event-log = <0x0>;
                        xlnx,have-sampled-metric-cnt = <0x1>;
                        xlnx,num-of-counters = <0x3>;
                        xlnx,metric-count-width = <0x20>;
                        xlnx,metrics-sample-count-width = <0x20>;
                        xlnx,global-count-width = <0x20>;
                        xlnx,metric-count-scale = <0x1>;
                        clocks = <&zynqmp_clk 0x1f>;
                        xlnx,enable-32bit-filter-id = <0x1>;
                        xlnx,ip-name = "psu_apm";
                        xlnx,fifo-axis-tid-width = <0x1>;
                        xlnx,enable-advanced = <0x1>;
                        xlnx,can-clk-freq-hz = <0x2faf080>;
                        status = "okay";
                        xlnx,fifo-axis-tdata-width = <0x38>;
                        xlnx,fifo-axis-depth = <0x20>;
                        xlnx,name = "psu_apm_1";
                        phandle = <0x2b>;
                };

                perf_monitor_ddr: perf-monitor@fd0b0000 {
                        compatible = "xlnx,axi-perf-monitor";
                        reg = <0x0 0xfd0b0000 0x0 0x10000>;
                        interrupts = <0x0 0x7b 0x4>;
                        interrupt-parent = <&gic>;
                        xlnx,enable-profile = <0x0>;
                        xlnx,enable-trace = <0x0>;
                        xlnx,num-monitor-slots = <0x6>;
                        xlnx,enable-event-count = <0x1>;
                        xlnx,enable-event-log = <0x0>;
                        xlnx,have-sampled-metric-cnt = <0x1>;
                        xlnx,num-of-counters = <0xa>;
                        xlnx,metric-count-width = <0x20>;
                        xlnx,metrics-sample-count-width = <0x20>;
                        xlnx,global-count-width = <0x20>;
                        xlnx,metric-count-scale = <0x1>;
                        clocks = <&zynqmp_clk 0x1c>;
                        xlnx,enable-32bit-filter-id = <0x1>;
                        xlnx,ip-name = "psu_apm";
                        xlnx,fifo-axis-tid-width = <0x1>;
                        xlnx,enable-advanced = <0x1>;
                        xlnx,can-clk-freq-hz = <0x2faf080>;
                        status = "okay";
                        xlnx,fifo-axis-tdata-width = <0x38>;
                        xlnx,fifo-axis-depth = <0x20>;
                        xlnx,name = "psu_apm_0";
                        phandle = <0x2a>;
                };

                perf_monitor_cci: perf-monitor@fd490000 {
                        compatible = "xlnx,axi-perf-monitor";
                        reg = <0x0 0xfd490000 0x0 0x10000>;
                        interrupts = <0x0 0x7b 0x4>;
                        interrupt-parent = <&gic>;
                        xlnx,enable-profile = <0x0>;
                        xlnx,enable-trace = <0x0>;
                        xlnx,num-monitor-slots = <0x1>;
                        xlnx,enable-event-count = <0x1>;
                        xlnx,enable-event-log = <0x0>;
                        xlnx,have-sampled-metric-cnt = <0x1>;
                        xlnx,num-of-counters = <0x3>;
                        xlnx,metric-count-width = <0x20>;
                        xlnx,metrics-sample-count-width = <0x20>;
                        xlnx,global-count-width = <0x20>;
                        xlnx,metric-count-scale = <0x1>;
                        clocks = <&zynqmp_clk 0x1c>;
                        xlnx,enable-32bit-filter-id = <0x1>;
                        xlnx,ip-name = "psu_apm";
                        xlnx,fifo-axis-tid-width = <0x1>;
                        xlnx,enable-advanced = <0x1>;
                        xlnx,can-clk-freq-hz = <0x2faf080>;
                        status = "okay";
                        xlnx,fifo-axis-tdata-width = <0x38>;
                        xlnx,fifo-axis-depth = <0x20>;
                        xlnx,name = "psu_apm_5";
                        phandle = <0x2d>;
                };

                perf_monitor_lpd: perf-monitor@ffa10000 {
                        compatible = "xlnx,axi-perf-monitor";
                        reg = <0x0 0xffa10000 0x0 0x10000>;
                        interrupts = <0x0 0x19 0x4>;
                        interrupt-parent = <&gic>;
                        xlnx,enable-profile = <0x0>;
                        xlnx,enable-trace = <0x0>;
                        xlnx,num-monitor-slots = <0x1>;
                        xlnx,enable-event-count = <0x1>;
                        xlnx,enable-event-log = <0x0>;
                        xlnx,have-sampled-metric-cnt = <0x1>;
                        xlnx,num-of-counters = <0x3>;
                        xlnx,metric-count-width = <0x20>;
                        xlnx,metrics-sample-count-width = <0x20>;
                        xlnx,global-count-width = <0x20>;
                        xlnx,metric-count-scale = <0x1>;
                        clocks = <&zynqmp_clk 0x1f>;
                        xlnx,enable-32bit-filter-id = <0x1>;
                        xlnx,ip-name = "psu_apm";
                        xlnx,fifo-axis-tid-width = <0x1>;
                        xlnx,enable-advanced = <0x1>;
                        xlnx,can-clk-freq-hz = <0x2faf080>;
                        status = "okay";
                        xlnx,fifo-axis-tdata-width = <0x38>;
                        xlnx,fifo-axis-depth = <0x20>;
                        xlnx,name = "psu_apm_2";
                        phandle = <0x2c>;
                };

                qspi: spi@ff0f0000 {
                        bootph-all;
                        compatible = "xlnx,zynqmp-qspi-1.0";
                        status = "okay";
                        clock-names = "ref_clk", "pclk";
                        interrupts = <0x0 0xf 0x4>;
                        interrupt-parent = <&gic>;
                        num-cs = <0x2>;
                        reg = <0x0 0xff0f0000 0x0 0x1000 0x0 0xc0000000 0x0 0x8000000>;
                        #address-cells = <0x1>;
                        #size-cells = <0x0>;
                        power-domains = <&zynqmp_firmware 0x2d>;
                        clocks = <&zynqmp_clk 0x35>,
                         <&zynqmp_clk 0x1f>;
                        xlnx,is-cache-coherent = <0x0>;
                        xlnx,qspi-fbclk = <0x0>;
                        xlnx,tz-nonsecure = <0x1>;
                        xlnx,qspi-clk-freq-hz = <0x11e19751>;
                        xlnx,bus-width = <0x2>;
                        xlnx,ip-name = "psu_qspi";
                        xlnx,qspi-board-interface = "custom";
                        spi-rx-bus-width = <0x4>;
                        xlnx,connection-mode = <0x2>;
                        spi-tx-bus-width = <0x4>;
                        xlnx,clock-freq = <0x11e19751>;
                        xlnx,fb-clk = <0x1>;
                        xlnx,qspi-mode = <0x2>;
                        xlnx,name = "psu_qspi_0";
                        xlnx,qspi-bus-width = <0x2>;
                        is-dual = <0x1>;
                        phandle = <0x60>;
                };

                psgtr: phy@fd400000 {
                        compatible = "xlnx,zynqmp-psgtr-v1.1";
                        status = "okay";
                        reg = <0x0 0xfd400000 0x0 0x40000 0x0 0xfd3d0000 0x0 0x1000>;
                        reg-names = "serdes", "siou";
                        #phy-cells = <0x4>;
                        xlnx,ip-name = "psu_serdes";
                        xlnx,name = "psu_serdes";
                        phandle = <0x6b>;
                };

                rtc: rtc@ffa60000 {
                        compatible = "xlnx,zynqmp-rtc";
                        status = "okay";
                        reg = <0x0 0xffa60000 0x0 0x100>;
                        interrupt-parent = <&gic>;
                        interrupts = <0x0 0x1a 0x4 0x0 0x1b 0x4>;
                        interrupt-names = "alarm", "sec";
                        calibration = <0x7fff>;
                        xlnx,ip-name = "psu_rtc";
                        xlnx,name = "psu_rtc";
                        phandle = <0x69>;
                };

                sdhci1: mmc@ff170000 {
                        bootph-all;
                        compatible = "xlnx,zynqmp-8.9a", "arasan,sdhci-8.9a";
                        status = "okay";
                        interrupt-parent = <&gic>;
                        interrupts = <0x0 0x31 0x4>;
                        reg = <0x0 0xff170000 0x0 0x1000>;
                        clock-names = "clk_xin", "clk_ahb";
                        #clock-cells = <0x1>;
                        clock-output-names = "clk_out_sd1", "clk_in_sd1";
                        power-domains = <&zynqmp_firmware 0x28>;
                        resets = <&zynqmp_reset 0x27>;
                        clocks = <&zynqmp_clk 0x37>,
                         <&zynqmp_clk 0x1f>;
                        assigned-clocks = <&zynqmp_clk 0x37>;
                        xlnx,sd-board-interface = "custom";
                        xlnx,is-cache-coherent = <0x0>;
                        xlnx,clk-50-ddr-otap-dly = <0x0>;
                        xlnx,clk-50-sdr-itap-dly = <0x15>;
                        xlnx,has-emio = <0x0>;
                        clock-frequency = <0xbebba31>;
                        xlnx,tz-nonsecure = <0x1>;
                        xlnx,clk-100-sdr-otap-dly = <0x0>;
                        xlnx,mio-bank = <0x1>;
                        xlnx,ip-name = "psu_sd";
                        xlnx,bus-width = <0x4>;
                        xlnx,card-detect = <0x1>;
                        xlnx,has-wp = <0x0>;
                        xlnx,has-cd = <0x1>;
                        xlnx,slot-type = <0x2>;
                        xlnx,clk-50-sdr-otap-dly = <0x5>;
                        xlnx,clk-50-ddr-itap-dly = <0x0>;
                        xlnx,has-power = <0x0>;
                        xlnx,clk-200-sdr-otap-dly = <0x0>;
                        xlnx,sdio-clk-freq-hz = <0xbebba31>;
                        xlnx,write-protect = <0x0>;
                        xlnx,name = "psu_sd_1";
                        phandle = <0x6a>;
                };

                smmu: iommu@fd800000 {
                        compatible = "arm,mmu-500";
                        reg = <0x0 0xfd800000 0x0 0x20000>;
                        #iommu-cells = <0x1>;
                        status = "okay";
                        #global-interrupts = <0x1>;
                        interrupt-parent = <&gic>;
                        interrupts = <0x0 0x9b 0x4 0x0 0x9b 0x4 0x0 0x9b 0x4 0x0 0x9b 0x4 0x0 0x9b 0x4 0x0 0x9b 0x4 0x0 0x9b 0x4 0x0 0x9b 0x4 0x0 0x9b 0x4 0x0 0x9b 0x4 0x0 0x9b 0x4 0x0 0x9b 0x4 0x0 0x9b 0x4 0x0 0x9b 0x4 0x0 0x9b 0x4 0x0 0x9b 0x4 0x0 0x9b 0x4>;
                        xlnx,ip-name = "psu_smmu_gpv";
                        xlnx,name = "psu_smmu_gpv";
                        phandle = <0x6d>;
                };

                uart0: serial@ff000000 {
                        bootph-all;
                        compatible = "xlnx,zynqmp-uart", "cdns,uart-r1p12";
                        status = "okay";
                        interrupt-parent = <&gic>;
                        interrupts = <0x0 0x15 0x4>;
                        reg = <0x0 0xff000000 0x0 0x1000>;
                        clock-names = "uart_clk", "pclk";
                        power-domains = <&zynqmp_firmware 0x21>;
                        resets = <&zynqmp_reset 0x22>;
                        clocks = <&zynqmp_clk 0x38>,
                         <&zynqmp_clk 0x1f>;
                        assigned-clocks = <&zynqmp_clk 0x38>;
                        xlnx,clock-freq = <0x5f5dd19>;
                        u-boot,dm-pre-reloc;
                        xlnx,uart-board-interface = "custom";
                        xlnx,has-modem = <0x0>;
                        xlnx,ip-name = "psu_uart";
                        xlnx,baudrate = <0x1c200>;
                        cts-override;
                        port-number = <0x0>;
                        xlnx,uart-clk-freq-hz = <0x5f5dd19>;
                        xlnx,name = "psu_uart_0";
                        phandle = <0x6f>;
                };

                uart1: serial@ff010000 {
                        bootph-all;
                        compatible = "xlnx,zynqmp-uart", "cdns,uart-r1p12";
                        status = "okay";
                        interrupt-parent = <&gic>;
                        interrupts = <0x0 0x16 0x4>;
                        reg = <0x0 0xff010000 0x0 0x1000>;
                        clock-names = "uart_clk", "pclk";
                        power-domains = <&zynqmp_firmware 0x22>;
                        resets = <&zynqmp_reset 0x23>;
                        clocks = <&zynqmp_clk 0x39>,
                         <&zynqmp_clk 0x1f>;
                        assigned-clocks = <&zynqmp_clk 0x39>;
                        xlnx,clock-freq = <0x5f5dd19>;
                        u-boot,dm-pre-reloc;
                        xlnx,uart-board-interface = "custom";
                        xlnx,has-modem = <0x0>;
                        xlnx,ip-name = "psu_uart";
                        xlnx,baudrate = <0x1c200>;
                        cts-override;
                        port-number = <0x0>;
                        xlnx,uart-clk-freq-hz = <0x5f5dd19>;
                        xlnx,name = "psu_uart_1";
                        phandle = <0x70>;
                };

                xilinx_ams: ams@ffa50000 {
                        compatible = "xlnx,zynqmp-ams";
                        interrupt-parent = <&gic>;
                        interrupts = <0x0 0x38 0x4>;
                        reg = <0x0 0xffa50000 0x0 0x800>;
                        #address-cells = <0x1>;
                        #size-cells = <0x1>;
                        #io-channel-cells = <0x1>;
                        ranges = <0x0 0x0 0xffa50800 0x800>;
                        clocks = <&zynqmp_clk 0x46>;
                        status = "okay";
                        xlnx,clock-freq = <0x31>;
                        xlnx,ip-name = "psu_ams";
                        xlnx,name = "psu_ams";
                        phandle = <0x29>;

                        ams_ps: ams-ps@0 {
                                compatible = "xlnx,zynqmp-ams-ps";
                                status = "okay";
                                reg = <0x0 0x400>;
                                phandle = <0x5>;
                        };

                        ams_pl: ams-pl@400 {
                                compatible = "xlnx,zynqmp-ams-pl";
                                status = "okay";
                                reg = <0x400 0x400>;
                                phandle = <0x6>;
                        };
                };

                coresight_0: coresight@fe800000 {
                        compatible = "xlnx,coresight-1.0";
                        status = "okay";
                        reg = <0x0 0xfe800000 0x0 0x10000>;
                        xlnx,ip-name = "psu_coresight_0";
                        xlnx,name = "psu_coresight_0";
                        phandle = <0x31>;
                };

                csudma_0: dma@ffc80000 {
                        status = "okay";
                        compatible = "xlnx,zynqmp-csudma-1.0";
                        interrupt-parent = <&gic>;
                        interrupts = <0x0 0x56 0x4>;
                        reg = <0x0 0xffc80000 0x0 0x40000>;
                        xlnx,ip-name = "psu_csudma";
                        xlnx,dma-type = <0x0>;
                        xlnx,name = "psu_csudma";
                        phandle = <0x35>;
                };

                ipi0: ipi@ff300000 {
                        status = "okay";
                        compatible = "xlnx,zynqmp-ipi-mailbox";
                        interrupt-parent = <&gic>;
                        interrupts = <0x0 0x23 0x4>;
                        reg = <0x0 0xff300000 0x0 0x20>;
                        xlnx,ipi-bitmask = <0x1>;
                        xlnx,ipi-id = <0x0>;
                        xlnx,ipi-buf-index = <0x2>;
                        #address-cells = <0x2>;
                        #size-cells = <0x2>;
                        bootph-all;
                        ranges;
                        xlnx,cpu-name = "APU";
                        xlnx,buffer-base = <0xff990400>;
                        xlnx,base-address = <0xff300000>;
                        xlnx,buffer-index = <0x2>;
                        xlnx,ip-name = "psu_ipi";
                        xlnx,ipi-target-count = <0x7>;
                        xlnx,int-id = <0x43>;
                        xlnx,bit-position = <0x0>;
                        xlnx,name = "psu_ipi_0";
                        phandle = <0x10>;

                        psu_ipi_0_0: child@0 {
                                xlnx,ipi-bitmask = <0x1>;
                                xlnx,ipi-rsp-msg-buf = <0xff9904a0>;
                                xlnx,ipi-id = <0x0>;
                                xlnx,ipi-buf-index = <0x2>;
                                xlnx,ipi-req-msg-buf = <0xff990480>;
                                phandle = <0xdd>;
                        };

                        psu_ipi_0_1: child@1 {
                                xlnx,ipi-bitmask = <0x100>;
                                xlnx,ipi-rsp-msg-buf = <0xff990420>;
                                xlnx,ipi-id = <0x1>;
                                xlnx,ipi-buf-index = <0x0>;
                                xlnx,ipi-req-msg-buf = <0xff990400>;
                                phandle = <0xde>;
                        };

                        psu_ipi_0_2: child@2 {
                                xlnx,ipi-bitmask = <0x200>;
                                xlnx,ipi-rsp-msg-buf = <0xff990460>;
                                xlnx,ipi-id = <0x2>;
                                xlnx,ipi-buf-index = <0x1>;
                                xlnx,ipi-req-msg-buf = <0xff990440>;
                                phandle = <0xdf>;
                        };

                        psu_ipi_0_3: child@3 {
                                xlnx,ipi-bitmask = <0x10000>;
                                xlnx,ipi-rsp-msg-buf = <0xff9905e0>;
                                xlnx,ipi-id = <0x3>;
                                xlnx,ipi-buf-index = <0x7>;
                                xlnx,ipi-req-msg-buf = <0xff9905c0>;
                                phandle = <0xe0>;
                        };

                        psu_ipi_0_4: child@4 {
                                xlnx,ipi-bitmask = <0x20000>;
                                xlnx,ipi-rsp-msg-buf = <0xff9905e0>;
                                xlnx,ipi-id = <0x4>;
                                xlnx,ipi-buf-index = <0x7>;
                                xlnx,ipi-req-msg-buf = <0xff9905c0>;
                                phandle = <0xe1>;
                        };

                        psu_ipi_0_5: child@5 {
                                xlnx,ipi-bitmask = <0x40000>;
                                xlnx,ipi-rsp-msg-buf = <0xff9905e0>;
                                xlnx,ipi-id = <0x5>;
                                xlnx,ipi-buf-index = <0x7>;
                                xlnx,ipi-req-msg-buf = <0xff9905c0>;
                                phandle = <0xe2>;
                        };

                        psu_ipi_0_6: child@6 {
                                xlnx,ipi-bitmask = <0x80000>;
                                xlnx,ipi-rsp-msg-buf = <0xff9905e0>;
                                xlnx,ipi-id = <0x6>;
                                xlnx,ipi-buf-index = <0x7>;
                                xlnx,ipi-req-msg-buf = <0xff9905c0>;
                                phandle = <0xe3>;
                        };
                };

                psu_r5_tcm_ram_global: psu_r5_tcm_ram@ffe00000 {
                        compatible = "xlnx,psu-r5-tcm-ram-1.0", "mmio-sram";
                        status = "okay";
                        power-domains = <&zynqmp_firmware 0xf>;
                        xlnx,ip-name = "psu_r5_tcm_ram";
                        reg = <0x0 0xffe00000 0x0 0x40000>;
                        xlnx,name = "psu_r5_tcm_ram_global";
                        phandle = <0x66>;
                };

                psu_r5_tcm_ram_0: psu_r5_tcm_ram@0 {
                        compatible = "xlnx,psu-r5-tcm-ram-1.0";
                        status = "okay";
                        power-domains = <&zynqmp_firmware 0xf>;
                        xlnx,ip-name = "psu_r5_tcm_ram";
                        reg = <0x0 0x0 0x0 0x40000>;
                        xlnx,name = "psu_r5_tcm_ram_0";
                        phandle = <0x7a>;
                };

                psu_r5_1_btcm: psu_r5_1_btcm@20000 {
                        xlnx,power-domain = <0x10>;
                        compatible = "xlnx,psu-r5-1-btcm-1.0";
                        status = "okay";
                        power-domains = <&zynqmp_firmware 0x12>;
                        xlnx,ip-name = "psu_r5_1_btcm";
                        xlnx,bank-size = <0x10000>;
                        reg = <0x0 0x20000 0x0 0x10000>;
                        xlnx,name = "psu_r5_1_btcm";
                        phandle = <0x7f>;
                };

                psu_r5_1_btcm_global: psu_r5_1_btcm_global@ffeb0000 {
                        compatible = "xlnx,psu-r5-1-btcm-global-1.0", "mmio-sram";
                        status = "okay";
                        power-domains = <&zynqmp_firmware 0x12>;
                        xlnx,ip-name = "psu_r5_1_btcm_global";
                        reg = <0x0 0xffeb0000 0x0 0x10000>;
                        xlnx,name = "psu_r5_1_btcm_global";
                        phandle = <0x65>;
                };

                psu_r5_1_atcm: psu_r5_1_atcm@0 {
                        xlnx,power-domain = <0xf>;
                        compatible = "xlnx,psu-r5-1-atcm-1.0";
                        status = "okay";
                        power-domains = <&zynqmp_firmware 0x11>;
                        xlnx,ip-name = "psu_r5_1_atcm";
                        xlnx,bank-size = <0x10000>;
                        reg = <0x0 0x0 0x0 0x10000>;
                        xlnx,name = "psu_r5_1_atcm";
                        phandle = <0x7e>;
                };

                psu_r5_1_atcm_global: psu_r5_1_atcm_global@ffe90000 {
                        compatible = "xlnx,psu-r5-1-atcm-global-1.0", "mmio-sram";
                        status = "okay";
                        power-domains = <&zynqmp_firmware 0x11>;
                        xlnx,ip-name = "psu_r5_1_atcm_global";
                        reg = <0x0 0xffe90000 0x0 0x10000>;
                        xlnx,name = "psu_r5_1_atcm_global";
                        phandle = <0x64>;
                };

                psu_r5_0_btcm_lockstep: psu_r5_0_btcm_lockstep@ffe30000 {
                        compatible = "xlnx,psu-r5-0-btcm-lockstep-1.0", "mmio-sram";
                        status = "okay";
                        power-domains = <&zynqmp_firmware 0x10>;
                        xlnx,ip-name = "psu_r5_0_btcm_lockstep";
                        xlnx,is-hierarchy;
                        reg = <0x0 0xffe30000 0x0 0x10000>;
                        xlnx,name = "psu_r5_0_btcm_lockstep";
                        phandle = <0x113>;
                };

                psu_r5_0_btcm: psu_r5_0_btcm@20000 {
                        xlnx,power-domain = <0x12>;
                        compatible = "xlnx,psu-r5-0-btcm-1.0";
                        status = "okay";
                        power-domains = <&zynqmp_firmware 0x10>;
                        xlnx,ip-name = "psu_r5_0_btcm";
                        xlnx,bank-size = <0x10000>;
                        reg = <0x0 0x20000 0x0 0x10000>;
                        xlnx,name = "psu_r5_0_btcm";
                        phandle = <0x79>;
                };

                psu_r5_0_btcm_global: psu_r5_0_btcm_global@ffe20000 {
                        compatible = "xlnx,psu-r5-0-btcm-global-1.0", "mmio-sram";
                        status = "okay";
                        power-domains = <&zynqmp_firmware 0x10>;
                        xlnx,ip-name = "psu_r5_0_btcm_global";
                        reg = <0x0 0xffe20000 0x0 0x10000>;
                        xlnx,name = "psu_r5_0_btcm_global";
                        phandle = <0x63>;
                };

                psu_r5_0_atcm_lockstep: psu_r5_0_atcm_lockstep@ffe10000 {
                        compatible = "xlnx,psu-r5-0-atcm-lockstep-1.0", "mmio-sram";
                        status = "okay";
                        power-domains = <&zynqmp_firmware 0xf>;
                        xlnx,ip-name = "psu_r5_0_atcm_lockstep";
                        xlnx,is-hierarchy;
                        reg = <0x0 0xffe10000 0x0 0x10000>;
                        xlnx,name = "psu_r5_0_atcm_lockstep";
                        phandle = <0x114>;
                };

                psu_r5_0_atcm: psu_r5_0_atcm@0 {
                        xlnx,power-domain = <0x11>;
                        compatible = "xlnx,psu-r5-0-atcm-1.0";
                        status = "okay";
                        power-domains = <&zynqmp_firmware 0xf>;
                        xlnx,ip-name = "psu_r5_0_atcm";
                        xlnx,bank-size = <0x10000>;
                        reg = <0x0 0x0 0x0 0x10000>;
                        xlnx,name = "psu_r5_0_atcm";
                        phandle = <0x78>;
                };

                psu_r5_0_atcm_global: psu_r5_0_atcm_global@ffe00000 {
                        compatible = "xlnx,psu-r5-0-atcm-global-1.0", "mmio-sram";
                        status = "okay";
                        power-domains = <&zynqmp_firmware 0xf>;
                        xlnx,ip-name = "psu_r5_0_atcm_global";
                        reg = <0x0 0xffe00000 0x0 0x10000>;
                        xlnx,name = "psu_r5_0_atcm_global";
                        phandle = <0x62>;
                };

                psu_pmu_global_0: psu_pmu_global_0@ffd80000 {
                        compatible = "xlnx,psu-pmu-global-0-1.0";
                        status = "okay";
                        xlnx,ip-name = "psu_pmu_global_0";
                        reg = <0x0 0xffd80000 0x0 0x40000>;
                        xlnx,name = "psu_pmu_global_0";
                        phandle = <0x5f>;
                };

                psu_mbistjtag: psu_mbistjtag@ffcf0000 {
                        compatible = "xlnx,psu-mbistjtag-1.0";
                        status = "okay";
                        xlnx,ip-name = "psu_mbistjtag";
                        reg = <0x0 0xffcf0000 0x0 0x10000>;
                        xlnx,name = "psu_mbistjtag";
                        phandle = <0x5b>;
                };

                psu_rsa: psu_rsa@ffce0000 {
                        compatible = "xlnx,psu-rsa-1.0";
                        status = "okay";
                        xlnx,ip-name = "psu_rsa";
                        reg = <0x0 0xffce0000 0x0 0x10000>;
                        xlnx,name = "psu_rsa";
                        phandle = <0x68>;
                };

                psu_efuse: psu_efuse@ffcc0000 {
                        compatible = "xlnx,psu-efuse-1.0";
                        status = "okay";
                        xlnx,ip-name = "psu_efuse";
                        reg = <0x0 0xffcc0000 0x0 0x10000>;
                        xlnx,name = "psu_efuse";
                        phandle = <0x40>;
                };

                psu_csu_0: psu_csu@ffca0000 {
                        xlnx,csu-board-interface = "custom";
                        compatible = "xlnx,psu-csu-1.0";
                        status = "okay";
                        xlnx,can-clk-freq-hz = <0xaba9500>;
                        xlnx,ip-name = "psu_csu";
                        reg = <0x0 0xffca0000 0x0 0x10000>;
                        xlnx,name = "psu_csu_0";
                        phandle = <0x34>;
                };

                psu_fpd_gpv: psu_fpd_gpv@fd700000 {
                        compatible = "xlnx,psu-fpd-gpv-1.0";
                        status = "okay";
                        xlnx,ip-name = "psu_fpd_gpv";
                        reg = <0x0 0xfd700000 0x0 0x100000>;
                        xlnx,name = "psu_fpd_gpv";
                        phandle = <0x42>;
                };

                psu_cci_gpv: psu_cci_gpv@fd6e0000 {
                        compatible = "xlnx,psu-cci-gpv-1.0";
                        status = "okay";
                        xlnx,ip-name = "psu_cci_gpv";
                        reg = <0x0 0xfd6e0000 0x0 0x10000>;
                        xlnx,name = "psu_cci_gpv";
                        phandle = <0x2f>;
                };

                psu_fpd_slcr_secure: psu_fpd_slcr_secure@fd690000 {
                        compatible = "xlnx,psu-fpd-slcr-secure-1.0";
                        status = "okay";
                        xlnx,ip-name = "psu_fpd_slcr_secure";
                        reg = <0x0 0xfd690000 0x0 0x40000>;
                        xlnx,name = "psu_fpd_slcr_secure";
                        phandle = <0x44>;
                };

                psu_fpd_slcr: psu_fpd_slcr@fd610000 {
                        compatible = "xlnx,psu-fpd-slcr-1.0";
                        status = "okay";
                        xlnx,ip-name = "psu_fpd_slcr";
                        reg = <0x0 0xfd610000 0x0 0x80000>;
                        xlnx,name = "psu_fpd_slcr";
                        phandle = <0x43>;
                };

                psu_smmu_reg: psu_smmu_reg@fd5f0000 {
                        compatible = "xlnx,psu-smmu-reg-1.0";
                        status = "okay";
                        xlnx,ip-name = "psu_smmu_reg";
                        reg = <0x0 0xfd5f0000 0x0 0x10000>;
                        xlnx,name = "psu_smmu_reg";
                        phandle = <0x6e>;
                };

                psu_cci_reg: psu_cci_reg@fd5e0000 {
                        compatible = "xlnx,psu-cci-reg-1.0";
                        status = "okay";
                        xlnx,ip-name = "psu_cci_reg";
                        reg = <0x0 0xfd5e0000 0x0 0x10000>;
                        xlnx,name = "psu_cci_reg";
                        phandle = <0x30>;
                };

                psu_fpd_xmpu_cfg: psu_fpd_xmpu_cfg@fd5d0000 {
                        compatible = "xlnx,psu-fpd-xmpu-cfg-1.0";
                        status = "okay";
                        xlnx,ip-name = "psu_fpd_xmpu_cfg";
                        reg = <0x0 0xfd5d0000 0x0 0x10000>;
                        xlnx,name = "psu_fpd_xmpu_cfg";
                        phandle = <0x45>;
                };

                psu_apu: psu_apu@fd5c0000 {
                        compatible = "xlnx,psu-apu-1.0";
                        status = "okay";
                        xlnx,ip-name = "psu_apu";
                        reg = <0x0 0xfd5c0000 0x0 0x10000>;
                        xlnx,name = "psu_apu";
                        phandle = <0x2e>;
                };

                psu_fpd_xmpu_sink: psu_fpd_xmpu_sink@fd4f0000 {
                        compatible = "xlnx,psu-fpd-xmpu-sink-1.0";
                        status = "okay";
                        xlnx,ip-name = "psu_fpd_xmpu_sink";
                        reg = <0x0 0xfd4f0000 0x0 0x10000>;
                        xlnx,name = "psu_fpd_xmpu_sink";
                        phandle = <0x46>;
                };

                psu_siou: psu_siou@fd3d0000 {
                        compatible = "xlnx,psu-siou-1.0";
                        status = "okay";
                        xlnx,ip-name = "psu_siou";
                        reg = <0x0 0xfd3d0000 0x0 0x10000>;
                        xlnx,name = "psu_siou";
                        phandle = <0x6c>;
                };

                psu_afi_5: psu_afi@fd3b0000 {
                        compatible = "xlnx,psu-afi-1.0";
                        status = "okay";
                        xlnx,ip-name = "psu_afi";
                        reg = <0x0 0xfd3b0000 0x0 0x10000>;
                        xlnx,name = "psu_afi_5";
                        phandle = <0x27>;
                };

                psu_afi_4: psu_afi@fd3a0000 {
                        compatible = "xlnx,psu-afi-1.0";
                        status = "okay";
                        xlnx,ip-name = "psu_afi";
                        reg = <0x0 0xfd3a0000 0x0 0x10000>;
                        xlnx,name = "psu_afi_4";
                        phandle = <0x26>;
                };

                psu_afi_3: psu_afi@fd390000 {
                        compatible = "xlnx,psu-afi-1.0";
                        status = "okay";
                        xlnx,ip-name = "psu_afi";
                        reg = <0x0 0xfd390000 0x0 0x10000>;
                        xlnx,name = "psu_afi_3";
                        phandle = <0x25>;
                };

                psu_afi_2: psu_afi@fd380000 {
                        compatible = "xlnx,psu-afi-1.0";
                        status = "okay";
                        xlnx,ip-name = "psu_afi";
                        reg = <0x0 0xfd380000 0x0 0x10000>;
                        xlnx,name = "psu_afi_2";
                        phandle = <0x24>;
                };

                psu_afi_1: psu_afi@fd370000 {
                        compatible = "xlnx,psu-afi-1.0";
                        status = "okay";
                        xlnx,ip-name = "psu_afi";
                        reg = <0x0 0xfd370000 0x0 0x10000>;
                        xlnx,name = "psu_afi_1";
                        phandle = <0x23>;
                };

                psu_afi_0: psu_afi@fd360000 {
                        compatible = "xlnx,psu-afi-1.0";
                        status = "okay";
                        xlnx,ip-name = "psu_afi";
                        reg = <0x0 0xfd360000 0x0 0x10000>;
                        xlnx,name = "psu_afi_0";
                        phandle = <0x22>;
                };

                psu_crf_apb: psu_crf_apb@fd1a0000 {
                        compatible = "xlnx,psu-crf-apb-1.0";
                        status = "okay";
                        xlnx,ip-name = "psu_crf_apb";
                        reg = <0x0 0xfd1a0000 0x0 0x140000>;
                        xlnx,name = "psu_crf_apb";
                        phandle = <0x32>;
                };

                psu_ddr_qos_ctrl: psu_ddr_qos_ctrl@fd090000 {
                        compatible = "xlnx,psu-ddr-qos-ctrl-1.0";
                        status = "okay";
                        xlnx,ip-name = "psu_ddr_qos_ctrl";
                        reg = <0x0 0xfd090000 0x0 0x10000>;
                        xlnx,name = "psu_ddr_qos_ctrl";
                        phandle = <0x38>;
                };

                psu_ddr_phy: psu_ddr_phy@fd080000 {
                        compatible = "xlnx,psu-ddr-phy-1.0";
                        status = "okay";
                        xlnx,ip-name = "psu_ddr_phy";
                        reg = <0x0 0xfd080000 0x0 0x10000>;
                        xlnx,name = "psu_ddr_phy";
                        phandle = <0x37>;
                };

                psu_ddr_xmpu5_cfg: psu_ddr_xmpu5_cfg@fd050000 {
                        compatible = "xlnx,psu-ddr-xmpu5-cfg-1.0";
                        status = "okay";
                        xlnx,ip-name = "psu_ddr_xmpu5_cfg";
                        reg = <0x0 0xfd050000 0x0 0x10000>;
                        xlnx,name = "psu_ddr_xmpu5_cfg";
                        phandle = <0x3e>;
                };

                psu_ddr_xmpu4_cfg: psu_ddr_xmpu4_cfg@fd040000 {
                        compatible = "xlnx,psu-ddr-xmpu4-cfg-1.0";
                        status = "okay";
                        xlnx,ip-name = "psu_ddr_xmpu4_cfg";
                        reg = <0x0 0xfd040000 0x0 0x10000>;
                        xlnx,name = "psu_ddr_xmpu4_cfg";
                        phandle = <0x3d>;
                };

                psu_ddr_xmpu3_cfg: psu_ddr_xmpu3_cfg@fd030000 {
                        compatible = "xlnx,psu-ddr-xmpu3-cfg-1.0";
                        status = "okay";
                        xlnx,ip-name = "psu_ddr_xmpu3_cfg";
                        reg = <0x0 0xfd030000 0x0 0x10000>;
                        xlnx,name = "psu_ddr_xmpu3_cfg";
                        phandle = <0x3c>;
                };

                psu_ddr_xmpu2_cfg: psu_ddr_xmpu2_cfg@fd020000 {
                        compatible = "xlnx,psu-ddr-xmpu2-cfg-1.0";
                        status = "okay";
                        xlnx,ip-name = "psu_ddr_xmpu2_cfg";
                        reg = <0x0 0xfd020000 0x0 0x10000>;
                        xlnx,name = "psu_ddr_xmpu2_cfg";
                        phandle = <0x3b>;
                };

                psu_ddr_xmpu1_cfg: psu_ddr_xmpu1_cfg@fd010000 {
                        compatible = "xlnx,psu-ddr-xmpu1-cfg-1.0";
                        status = "okay";
                        xlnx,ip-name = "psu_ddr_xmpu1_cfg";
                        reg = <0x0 0xfd010000 0x0 0x10000>;
                        xlnx,name = "psu_ddr_xmpu1_cfg";
                        phandle = <0x3a>;
                };

                psu_ddr_xmpu0_cfg: psu_ddr_xmpu0_cfg@fd000000 {
                        compatible = "xlnx,psu-ddr-xmpu0-cfg-1.0";
                        status = "okay";
                        xlnx,ip-name = "psu_ddr_xmpu0_cfg";
                        reg = <0x0 0xfd000000 0x0 0x10000>;
                        xlnx,name = "psu_ddr_xmpu0_cfg";
                        phandle = <0x39>;
                };

                psu_ocm_xmpu_cfg: psu_ocm_xmpu_cfg@ffa70000 {
                        compatible = "xlnx,psu-ocm-xmpu-cfg-1.0";
                        status = "okay";
                        xlnx,ip-name = "psu_ocm_xmpu_cfg";
                        reg = <0x0 0xffa70000 0x0 0x10000>;
                        xlnx,name = "psu_ocm_xmpu_cfg";
                        phandle = <0x5e>;
                };

                psu_lpd_xppu_sink: psu_lpd_xppu_sink@ff9c0000 {
                        compatible = "xlnx,psu-lpd-xppu-sink-1.0";
                        status = "okay";
                        xlnx,ip-name = "psu_lpd_xppu_sink";
                        reg = <0x0 0xff9c0000 0x0 0x10000>;
                        xlnx,name = "psu_lpd_xppu_sink";
                        phandle = <0x5a>;
                };

                psu_afi_6: psu_afi@ff9b0000 {
                        compatible = "xlnx,psu-afi-1.0";
                        status = "okay";
                        xlnx,ip-name = "psu_afi";
                        reg = <0x0 0xff9b0000 0x0 0x10000>;
                        xlnx,name = "psu_afi_6";
                        phandle = <0x28>;
                };

                psu_rpu: psu_rpu@ff9a0000 {
                        xlnx,is-cache-coherent = <0x0>;
                        compatible = "xlnx,psu-rpu-1.0";
                        status = "okay";
                        xlnx,ip-name = "psu_rpu";
                        reg = <0x0 0xff9a0000 0x0 0x10000>;
                        xlnx,name = "psu_rpu";
                        phandle = <0x67>;
                };

                psu_crl_apb: psu_crl_apb@ff5e0000 {
                        compatible = "xlnx,psu-crl-apb-1.0";
                        status = "okay";
                        xlnx,ip-name = "psu_crl_apb";
                        reg = <0x0 0xff5e0000 0x0 0x280000>;
                        xlnx,name = "psu_crl_apb";
                        phandle = <0x33>;
                };

                psu_lpd_slcr_secure: psu_lpd_slcr_secure@ff4b0000 {
                        compatible = "xlnx,psu-lpd-slcr-secure-1.0";
                        status = "okay";
                        xlnx,ip-name = "psu_lpd_slcr_secure";
                        reg = <0x0 0xff4b0000 0x0 0x30000>;
                        xlnx,name = "psu_lpd_slcr_secure";
                        phandle = <0x58>;
                };

                psu_lpd_slcr: psu_lpd_slcr@ff410000 {
                        compatible = "xlnx,psu-lpd-slcr-1.0";
                        status = "okay";
                        xlnx,ip-name = "psu_lpd_slcr";
                        reg = <0x0 0xff410000 0x0 0xa0000>;
                        xlnx,name = "psu_lpd_slcr";
                        phandle = <0x57>;
                };

                psu_ctrl_ipi: PERIPHERAL@ff380000 {
                        compatible = "xlnx,PERIPHERAL-1.0";
                        reg = <0x0 0xff380000 0x0 0x80000>;
                        phandle = <0x36>;
                };

                psu_message_buffers: PERIPHERAL@ff990000 {
                        compatible = "xlnx,PERIPHERAL-1.0";
                        reg = <0x0 0xff990000 0x0 0x10000>;
                        phandle = <0x5c>;
                };

                psu_iou_scntrs: psu_iou_scntrs@ff260000 {
                        compatible = "xlnx,psu-iou-scntrs-1.0";
                        status = "okay";
                        xlnx,ip-name = "psu_iou_scntrs";
                        reg = <0x0 0xff260000 0x0 0x10000>;
                        xlnx,name = "psu_iou_scntrs";
                        phandle = <0x54>;
                };

                psu_iou_scntr: psu_iou_scntr@ff250000 {
                        compatible = "xlnx,psu-iou-scntr-1.0";
                        status = "okay";
                        xlnx,ip-name = "psu_iou_scntr";
                        reg = <0x0 0xff250000 0x0 0x10000>;
                        xlnx,name = "psu_iou_scntr";
                        phandle = <0x53>;
                };

                psu_iousecure_slcr: psu_iousecure_slcr@ff240000 {
                        compatible = "xlnx,psu-iousecure-slcr-1.0";
                        status = "okay";
                        xlnx,ip-name = "psu_iousecure_slcr";
                        reg = <0x0 0xff240000 0x0 0x10000>;
                        xlnx,name = "psu_iousecure_slcr";
                        phandle = <0x55>;
                };

                psu_iouslcr_0: psu_iouslcr@ff180000 {
                        compatible = "xlnx,psu-iouslcr-1.0";
                        status = "okay";
                        xlnx,ip-name = "psu_iouslcr";
                        reg = <0x0 0xff180000 0x0 0xc0000>;
                        xlnx,name = "psu_iouslcr_0";
                        phandle = <0x56>;
                };

                psu_qspi_linear_0: psu_qspi_linear@c0000000 {
                        reg = <0x0 0xc0000000 0x0 0x20000000>;
                        phandle = <0x117>;
                };

                gic: interrupt-controller@f9010000 {
                        phandle = <0x19>;
                        xlnx,name = "psu_acpu_gic";
                        xlnx,ip-name = "psu_acpu_gic";
                        status = "okay";
                        interrupts = <0x1 0x9 0xf04>;
                        interrupt-parent = <&gic>;
                        interrupt-controller;
                        reg = <0x0 0xf9010000 0x0 0x10000 0x0 0xf9020000 0x0 0x20000 0x0 0xf9040000 0x0 0x20000 0x0 0xf9060000 0x0 0x20000>;
                        #interrupt-cells = <0x3>;
                        compatible = "arm,gic-400";
                };
        };

        amba_xppu: indirect-bus@1 {
                compatible = "indirect-bus";
                #address-cells = <0x2>;
                #size-cells = <0x2>;
                phandle = <0x118>;

                lpd_xppu: xppu@ff980000 {
                        compatible = "xlnx,xppu";
                        #firewall-cells = <0x0>;
                        reg = <0x0 0xff980000 0x0 0x1000>;
                        status = "okay";
                        xlnx,ip-name = "psu_lpd_xppu";
                        xlnx,name = "psu_lpd_xppu";
                        phandle = <0x59>;
                };
        };

        binman: binman {
                phandle = <0x119>;
        };

        pss_ref_clk: pss-ref-clk {
                bootph-all;
                compatible = "fixed-clock";
                #clock-cells = <0x0>;
                clock-frequency = <0x1fca055>;
                clock-output-names = "pss_ref_clk";
                phandle = <0x8d>;
        };

        video_clk: video-clk {
                bootph-all;
                compatible = "fixed-clock";
                #clock-cells = <0x0>;
                clock-frequency = <0x19bfcc0>;
                clock-output-names = "video_clk";
                phandle = <0x8e>;
        };

        pss_alt_ref_clk: pss-alt-ref-clk {
                bootph-all;
                compatible = "fixed-clock";
                #clock-cells = <0x0>;
                clock-frequency = <0x0>;
                clock-output-names = "pss_alt_ref_clk";
                phandle = <0x8f>;
        };

        gt_crx_ref_clk: gt-crx-ref-clk {
                bootph-all;
                compatible = "fixed-clock";
                #clock-cells = <0x0>;
                clock-frequency = <0x66ff300>;
                clock-output-names = "gt_crx_ref_clk";
                phandle = <0x91>;
        };

        aux_ref_clk: aux-ref-clk {
                bootph-all;
                compatible = "fixed-clock";
                #clock-cells = <0x0>;
                clock-frequency = <0x19bfcc0>;
                clock-output-names = "aux_ref_clk";
                phandle = <0x90>;
        };

        amba_pl: amba_pl {
                ranges;
                compatible = "simple-bus";
                #address-cells = <0x2>;
                #size-cells = <0x2>;
                firmware-name = "sys_top_wrapper.bit.bin";
                phandle = <0x11a>;

                misc_clk_0: misc_clk_0 {
                        clock-div = <0x1>;
                        compatible = "fixed-factor-clock";
                        clock-mult = <0x1>;
                        clocks = <&zynqmp_clk 0x47>;
                        #clock-cells = <0x0>;
                        phandle = <0x9b>;
                };

                misc_clk_1: misc_clk_1 {
                        clock-div = <0x1>;
                        compatible = "fixed-factor-clock";
                        clock-mult = <0x2>;
                        clocks = <&zynqmp_clk 0x47>;
                        #clock-cells = <0x0>;
                        phandle = <0x9c>;
                };

                axi_bram_ctrl_0: axi_bram_ctrl_0@a0000000 {
                        xlnx,protocol = "AXI4";
                        xlnx,edk-special = "BRAM_CTRL";
                        compatible = "xlnx,axi-bram-ctrl-4.1", "xlnx,axi-bram-ctrl";
                        xlnx,ecc-onoff-reset-value = <0x0>;
                        xlnx,ecc-type = <0x0>;
                        xlnx,rd-cmd-optimization = <0x0>;
                        xlnx,memory-depth = <0x400>;
                        xlnx,use-ecc = <0x0>;
                        xlnx,fault-inject = <0x0>;
                        xlnx,ip-name = "axi_bram_ctrl";
                        reg = <0x0 0xa0000000 0x0 0x1000>;
                        xlnx,bmg-instance = "EXTERNAL";
                        clocks = <&misc_clk_0>;
                        xlnx,s-axi-ctrl-addr-width = <0x20>;
                        xlnx,read-latency = <0x1>;
                        xlnx,id-width = <0x0>;
                        xlnx,s-axi-supports-narrow-burst = <0x1>;
                        xlnx,supports-narrow-burst = <0x1>;
                        xlnx,single-port-bram = <0x1>;
                        xlnx,ecc = <0x0>;
                        xlnx,edk-iptype = "PERIPHERAL";
                        status = "okay";
                        clock-names = "s_axi_aclk";
                        xlnx,data-width = <0x20>;
                        xlnx,bram-addr-width = <0xa>;
                        xlnx,bram-inst-mode = "EXTERNAL";
                        xlnx,s-axi-ctrl-data-width = <0x20>;
                        xlnx,mem-depth = <0x400>;
                        xlnx,s-axi-id-width = <0x1>;
                        xlnx,name = "axi_bram_ctrl_0";
                        phandle = <0x8>;
                };

                axi_bram_ctrl_1: axi_bram_ctrl_1@a0001000 {
                        xlnx,protocol = "AXI4";
                        xlnx,edk-special = "BRAM_CTRL";
                        compatible = "xlnx,axi-bram-ctrl-4.1", "xlnx,axi-bram-ctrl";
                        xlnx,ecc-onoff-reset-value = <0x0>;
                        xlnx,ecc-type = <0x0>;
                        xlnx,rd-cmd-optimization = <0x0>;
                        xlnx,memory-depth = <0x400>;
                        xlnx,use-ecc = <0x0>;
                        xlnx,fault-inject = <0x0>;
                        xlnx,ip-name = "axi_bram_ctrl";
                        reg = <0x0 0xa0001000 0x0 0x1000>;
                        xlnx,bmg-instance = "EXTERNAL";
                        clocks = <&misc_clk_0>;
                        xlnx,s-axi-ctrl-addr-width = <0x20>;
                        xlnx,read-latency = <0x1>;
                        xlnx,id-width = <0x0>;
                        xlnx,s-axi-supports-narrow-burst = <0x1>;
                        xlnx,supports-narrow-burst = <0x1>;
                        xlnx,single-port-bram = <0x1>;
                        xlnx,ecc = <0x0>;
                        xlnx,edk-iptype = "PERIPHERAL";
                        status = "okay";
                        clock-names = "s_axi_aclk";
                        xlnx,data-width = <0x20>;
                        xlnx,bram-addr-width = <0xa>;
                        xlnx,bram-inst-mode = "EXTERNAL";
                        xlnx,s-axi-ctrl-data-width = <0x20>;
                        xlnx,mem-depth = <0x400>;
                        xlnx,s-axi-id-width = <0x1>;
                        xlnx,name = "axi_bram_ctrl_1";
                        phandle = <0xa>;
                };

                axi_bram_ctrl_2: axi_bram_ctrl_2@a0002000 {
                        xlnx,protocol = "AXI4";
                        xlnx,edk-special = "BRAM_CTRL";
                        compatible = "xlnx,axi-bram-ctrl-4.1", "xlnx,axi-bram-ctrl";
                        xlnx,ecc-onoff-reset-value = <0x0>;
                        xlnx,ecc-type = <0x0>;
                        xlnx,rd-cmd-optimization = <0x0>;
                        xlnx,memory-depth = <0x400>;
                        xlnx,use-ecc = <0x0>;
                        xlnx,fault-inject = <0x0>;
                        xlnx,ip-name = "axi_bram_ctrl";
                        reg = <0x0 0xa0002000 0x0 0x1000>;
                        xlnx,bmg-instance = "EXTERNAL";
                        clocks = <&misc_clk_0>;
                        xlnx,s-axi-ctrl-addr-width = <0x20>;
                        xlnx,read-latency = <0x1>;
                        xlnx,id-width = <0x0>;
                        xlnx,s-axi-supports-narrow-burst = <0x1>;
                        xlnx,supports-narrow-burst = <0x1>;
                        xlnx,single-port-bram = <0x1>;
                        xlnx,ecc = <0x0>;
                        xlnx,edk-iptype = "PERIPHERAL";
                        status = "okay";
                        clock-names = "s_axi_aclk";
                        xlnx,data-width = <0x20>;
                        xlnx,bram-addr-width = <0xa>;
                        xlnx,bram-inst-mode = "EXTERNAL";
                        xlnx,s-axi-ctrl-data-width = <0x20>;
                        xlnx,mem-depth = <0x400>;
                        xlnx,s-axi-id-width = <0x1>;
                        xlnx,name = "axi_bram_ctrl_2";
                        phandle = <0xc>;
                };

                axi_bram_ctrl_3: axi_bram_ctrl_3@a0003000 {
                        xlnx,protocol = "AXI4";
                        xlnx,edk-special = "BRAM_CTRL";
                        compatible = "xlnx,axi-bram-ctrl-4.1", "xlnx,axi-bram-ctrl";
                        xlnx,ecc-onoff-reset-value = <0x0>;
                        xlnx,ecc-type = <0x0>;
                        xlnx,rd-cmd-optimization = <0x0>;
                        xlnx,memory-depth = <0x400>;
                        xlnx,use-ecc = <0x0>;
                        xlnx,fault-inject = <0x0>;
                        xlnx,ip-name = "axi_bram_ctrl";
                        reg = <0x0 0xa0003000 0x0 0x1000>;
                        xlnx,bmg-instance = "EXTERNAL";
                        clocks = <&misc_clk_0>;
                        xlnx,s-axi-ctrl-addr-width = <0x20>;
                        xlnx,read-latency = <0x1>;
                        xlnx,id-width = <0x0>;
                        xlnx,s-axi-supports-narrow-burst = <0x1>;
                        xlnx,supports-narrow-burst = <0x1>;
                        xlnx,single-port-bram = <0x1>;
                        xlnx,ecc = <0x0>;
                        xlnx,edk-iptype = "PERIPHERAL";
                        status = "okay";
                        clock-names = "s_axi_aclk";
                        xlnx,data-width = <0x20>;
                        xlnx,bram-addr-width = <0xa>;
                        xlnx,bram-inst-mode = "EXTERNAL";
                        xlnx,s-axi-ctrl-data-width = <0x20>;
                        xlnx,mem-depth = <0x400>;
                        xlnx,s-axi-id-width = <0x1>;
                        xlnx,name = "axi_bram_ctrl_3";
                        phandle = <0xe>;
                };

                iodelay_if_0: iodelay_if@b0000000 {
                        compatible = "xlnx,iodelay-if-1.0.0";
                        status = "okay";
                        clock-names = "sys__clk";
                        xlnx,ip-name = "iodelay_if";
                        xlnx,edk-iptype = "PERIPHERAL";
                        xlnx,addr-width = <0x20>;
                        reg = <0x0 0xb0000000 0x0 0x10000>;
                        clocks = <&zynqmp_clk 0x47>;
                        xlnx,name = "iodelay_if_0";
                        phandle = <0x16>;
                };

                iodelay_if_0_dqs: iodelay_if@b0010000 {
                        compatible = "xlnx,iodelay-if-1.0.0";
                        status = "okay";
                        clock-names = "sys__clk";
                        xlnx,ip-name = "iodelay_if";
                        xlnx,edk-iptype = "PERIPHERAL";
                        xlnx,addr-width = <0x20>;
                        reg = <0x0 0xb0010000 0x0 0x10000>;
                        clocks = <&zynqmp_clk 0x47>;
                        xlnx,name = "iodelay_if_0_dqs";
                        phandle = <0x17>;
                };

                nvme_ctrl_0: nvme_ctrl@b0020000 {
                        xlnx,ext-pipe-sim;
                        compatible = "xlnx,nvme-ctrl-1.0";
                        xlnx,pl-link-cap-max-link-width = <0x10>;
                        xlnx,m0-axi-id-width = <0x1>;
                        xlnx,axi4-rq-tuser-width = <0x89>;
                        xlnx,pl-link-cap-max-link-speed = <0x4>;
                        xlnx,p-slot-width = <0x400>;
                        xlnx,axisten-if-mc-rx-straddle = <0x0>;
                        xlnx,axi4-rc-tuser-width = <0xa1>;
                        xlnx,axisten-if-rq-alignment-mode;
                        xlnx,s0-axi-addr-width = <0x20>;
                        xlnx,m0-axi-ruser-width = <0x1>;
                        xlnx,m0-axi-buser-width = <0x1>;
                        xlnx,ip-name = "nvme_ctrl";
                        xlnx,axisten-if-cq-alignment-mode;
                        xlnx,rq-avail-tag-idx = <0x8>;
                        xlnx,m0-axi-data-width = <0x40>;
                        xlnx,m0-axi-aruser-width = <0x1>;
                        xlnx,axisten-if-rc-alignment-mode;
                        reg = <0x0 0xb0020000 0x0 0x20000>;
                        clocks = <&zynqmp_clk 0x4a>,
                         <&misc_clk_1>,
                         <&misc_clk_1>,
                         <&zynqmp_clk 0x49>;
                        xlnx,axisten-if-rq-parity-check = <0x0>;
                        xlnx,axisten-if-cc-alignment-mode;
                        xlnx,keep-width = <0x10>;
                        xlnx,axisten-if-cq-parity-check = <0x0>;
                        xlnx,axisten-if-rc-parity-check = <0x0>;
                        xlnx,edk-iptype = "PERIPHERAL";
                        xlnx,m0-axi-wuser-width = <0x1>;
                        xlnx,axisten-if-enable-msg-route = "101111111111111111";
                        xlnx,axi4-cq-tuser-width = <0xb7>;
                        xlnx,axisten-if-cc-parity-check = <0x0>;
                        xlnx,p-slot-tag-width = <0xa>;
                        xlnx,pcie-data-width = <0x200>;
                        xlnx,m0-axi-awuser-width = <0x1>;
                        xlnx,rq-avail-tag = <0x100>;
                        xlnx,s0-axi-data-width = <0x20>;
                        status = "okay";
                        xlnx,axi4-cc-tuser-width = <0x51>;
                        clock-names = "m0_axi_aclk", "pcie_ref_clk_n", "pcie_ref_clk_p", "s0_axi_aclk";
                        xlnx,axisten-if-enable-rx-msg-intfc;
                        xlnx,m0-axi-addr-width = <0x20>;
                        xlnx,axisten-if-enable-client-tag = <0x1>;
                        xlnx,name = "nvme_ctrl_0";
                        phandle = <0x18>;
                };

                t4nfc_hlper_0: t4nfc_hlper@a0010000 {
                        xlnx,numberofways = <0x8>;
                        compatible = "xlnx,t4nfc-hlper-1.0.2";
                        status = "okay";
                        clock-names = "iClock";
                        xlnx,ip-name = "t4nfc_hlper";
                        xlnx,edk-iptype = "PERIPHERAL";
                        reg = <0x0 0xa0010000 0x0 0x10000>;
                        clocks = <&misc_clk_0>;
                        xlnx,name = "t4nfc_hlper_0";
                        phandle = <0x12>;
                };

                t4nfc_hlper_1: t4nfc_hlper@a0020000 {
                        xlnx,numberofways = <0x8>;
                        compatible = "xlnx,t4nfc-hlper-1.0.2";
                        status = "okay";
                        clock-names = "iClock";
                        xlnx,ip-name = "t4nfc_hlper";
                        xlnx,edk-iptype = "PERIPHERAL";
                        reg = <0x0 0xa0020000 0x0 0x10000>;
                        clocks = <&misc_clk_0>;
                        xlnx,name = "t4nfc_hlper_1";
                        phandle = <0x13>;
                };

                t4nfc_hlper_2: t4nfc_hlper@a0030000 {
                        xlnx,numberofways = <0x8>;
                        compatible = "xlnx,t4nfc-hlper-1.0.2";
                        status = "okay";
                        clock-names = "iClock";
                        xlnx,ip-name = "t4nfc_hlper";
                        xlnx,edk-iptype = "PERIPHERAL";
                        reg = <0x0 0xa0030000 0x0 0x10000>;
                        clocks = <&misc_clk_0>;
                        xlnx,name = "t4nfc_hlper_2";
                        phandle = <0x14>;
                };

                t4nfc_hlper_3: t4nfc_hlper@a0040000 {
                        xlnx,numberofways = <0x8>;
                        compatible = "xlnx,t4nfc-hlper-1.0.2";
                        status = "okay";
                        clock-names = "iClock";
                        xlnx,ip-name = "t4nfc_hlper";
                        xlnx,edk-iptype = "PERIPHERAL";
                        reg = <0x0 0xa0040000 0x0 0x10000>;
                        clocks = <&misc_clk_0>;
                        xlnx,name = "t4nfc_hlper_3";
                        phandle = <0x15>;
                };
        };

        axi_bram_ctrl_0_memory: memory@a0000000 {
                compatible = "xlnx,axi-bram-ctrl-4.1";
                xlnx,ip-name = "axi_bram_ctrl";
                device_type = "memory";
                memory_type = "memory";
                reg = <0x0 0xa0000000 0x0 0x1000>;
                phandle = <0x7>;
        };

        axi_bram_ctrl_1_memory: memory@a0001000 {
                compatible = "xlnx,axi-bram-ctrl-4.1";
                xlnx,ip-name = "axi_bram_ctrl";
                device_type = "memory";
                memory_type = "memory";
                reg = <0x0 0xa0001000 0x0 0x1000>;
                phandle = <0x9>;
        };

        axi_bram_ctrl_2_memory: memory@a0002000 {
                compatible = "xlnx,axi-bram-ctrl-4.1";
                xlnx,ip-name = "axi_bram_ctrl";
                device_type = "memory";
                memory_type = "memory";
                reg = <0x0 0xa0002000 0x0 0x1000>;
                phandle = <0xb>;
        };

        axi_bram_ctrl_3_memory: memory@a0003000 {
                compatible = "xlnx,axi-bram-ctrl-4.1";
                xlnx,ip-name = "axi_bram_ctrl";
                device_type = "memory";
                memory_type = "memory";
                reg = <0x0 0xa0003000 0x0 0x1000>;
                phandle = <0xd>;
        };

        psu_ocm_ram_0_memory: memory@FFFC0000 {
                compatible = "xlnx,psu-ocm-ram-0-1.0", "mmio-sram";
                xlnx,ip-name = "psu_ocm_ram_0";
                device_type = "memory";
                memory_type = "memory";
                reg = <0x0 0xfffc0000 0x0 0x40000>;
                phandle = <0xf>;
        };

        psu_ddr_0_memory: memory@0 {
                compatible = "xlnx,psu-ddr-1.0";
                xlnx,ip-name = "psu_ddr";
                device_type = "memory";
                memory_type = "memory";
                reg = <0x0 0x0 0x0 0x7ff00000 0x0 0x7ff00000 0x0 0x100000>;
                phandle = <0x11>;
        };

        psu_qspi_linear_0_memory: memory@c0000000 {
                compatible = "xlnx,psu-qspi-linear-1.0-memory";
                xlnx,ip-name = "psu_qspi_linear";
                device_type = "memory";
                memory_type = "linear_flash";
                reg = <0x0 0xc0000000 0x0 0x20000000>;
                phandle = <0x61>;
        };

        chosen {
                bootargs = "earlycon console=ttyPS0,115200 clk_ignore_unused init_fatal_sh=1";
                stdout-path = "serial0:115200n8";
        };

        aliases {
                serial0 = "/axi/serial@ff000000";
                spi0 = "/axi/spi@ff0f0000";
                serial1 = "/axi/serial@ff010000";
                serial2 = "/axi/coresight@fe800000";
                i2c0 = "/axi/i2c@ff030000";
                i2c1 = "/axi/i2c@ff020000";
                ethernet0 = "/axi/ethernet@ff0e0000";
        };

        __symbols__ {
                cpus_a53 = "/cpus-a53@0";
                psu_cortexa53_0 = "/cpus-a53@0/cpu@0";
                psu_cortexa53_1 = "/cpus-a53@0/cpu@1";
                psu_cortexa53_2 = "/cpus-a53@0/cpu@2";
                psu_cortexa53_3 = "/cpus-a53@0/cpu@3";
                L2 = "/cpus-a53@0/l2-cache";
                CPU_SLEEP_0 = "/cpus-a53@0/idle-states/cpu-sleep-0";
                cpu_opp_table = "/opp-table-cpu";
                zynqmp_ipi = "/zynqmp-ipi";
                ipi_mailbox_pmu1 = "/zynqmp-ipi/mailbox@ff9905c0";
                zynqmp_firmware = "/firmware/zynqmp-firmware";
                zynqmp_power = "/firmware/zynqmp-firmware/power-management";
                soc_revision = "/firmware/zynqmp-firmware/soc-nvmem/nvmem-layout/soc-revision@0";
                efuse_dna = "/firmware/zynqmp-firmware/soc-nvmem/nvmem-layout/efuse-dna@c";
                efuse_usr0 = "/firmware/zynqmp-firmware/soc-nvmem/nvmem-layout/efuse-usr0@20";
                efuse_usr1 = "/firmware/zynqmp-firmware/soc-nvmem/nvmem-layout/efuse-usr1@24";
                efuse_usr2 = "/firmware/zynqmp-firmware/soc-nvmem/nvmem-layout/efuse-usr2@28";
                efuse_usr3 = "/firmware/zynqmp-firmware/soc-nvmem/nvmem-layout/efuse-usr3@2c";
                efuse_usr4 = "/firmware/zynqmp-firmware/soc-nvmem/nvmem-layout/efuse-usr4@30";
                efuse_usr5 = "/firmware/zynqmp-firmware/soc-nvmem/nvmem-layout/efuse-usr5@34";
                efuse_usr6 = "/firmware/zynqmp-firmware/soc-nvmem/nvmem-layout/efuse-usr6@38";
                efuse_usr7 = "/firmware/zynqmp-firmware/soc-nvmem/nvmem-layout/efuse-usr7@3c";
                efuse_miscusr = "/firmware/zynqmp-firmware/soc-nvmem/nvmem-layout/efuse-miscusr@40";
                efuse_chash = "/firmware/zynqmp-firmware/soc-nvmem/nvmem-layout/efuse-chash@50";
                efuse_pufmisc = "/firmware/zynqmp-firmware/soc-nvmem/nvmem-layout/efuse-pufmisc@54";
                efuse_sec = "/firmware/zynqmp-firmware/soc-nvmem/nvmem-layout/efuse-sec@58";
                efuse_spkid = "/firmware/zynqmp-firmware/soc-nvmem/nvmem-layout/efuse-spkid@5c";
                efuse_aeskey = "/firmware/zynqmp-firmware/soc-nvmem/nvmem-layout/efuse-aeskey@60";
                efuse_ppk0hash = "/firmware/zynqmp-firmware/soc-nvmem/nvmem-layout/efuse-ppk0hash@a0";
                efuse_ppk1hash = "/firmware/zynqmp-firmware/soc-nvmem/nvmem-layout/efuse-ppk1hash@d0";
                efuse_pufuser = "/firmware/zynqmp-firmware/soc-nvmem/nvmem-layout/efuse-pufuser@100";
                zynqmp_pcap = "/firmware/zynqmp-firmware/pcap";
                zynqmp_reset = "/firmware/zynqmp-firmware/reset-controller";
                pinctrl0 = "/firmware/zynqmp-firmware/pinctrl";
                modepin_gpio = "/firmware/zynqmp-firmware/gpio";
                zynqmp_clk = "/firmware/zynqmp-firmware/clock-controller";
                fpga_full = "/fpga-region";
                tsens_apu = "/thermal-sensor-apu";
                tsens_rpu = "/thermal-sensor-rpu";
                tsens_pl = "/thermal-sensor-pl";
                apu_passive = "/thermal-zones/apu-thermal/trips/passive";
                apu_critical = "/thermal-zones/apu-thermal/trips/critical";
                amba_apu = "/apu-bus";
                amba_rpu = "/rpu-bus";
                amba = "/axi";
                imux = "/axi/interrupt-multiplex";
                psu_cortexa53_0_debug = "/axi/debug@fec10000";
                psu_cortexa53_1_debug = "/axi/debug@fed10000";
                psu_cortexa53_2_debug = "/axi/debug@fee10000";
                psu_cortexa53_3_debug = "/axi/debug@fef10000";
                fpd_dma_chan1 = "/axi/dma-controller@fd500000";
                fpd_dma_chan2 = "/axi/dma-controller@fd510000";
                fpd_dma_chan3 = "/axi/dma-controller@fd520000";
                fpd_dma_chan4 = "/axi/dma-controller@fd530000";
                fpd_dma_chan5 = "/axi/dma-controller@fd540000";
                fpd_dma_chan6 = "/axi/dma-controller@fd550000";
                fpd_dma_chan7 = "/axi/dma-controller@fd560000";
                fpd_dma_chan8 = "/axi/dma-controller@fd570000";
                gpu = "/axi/gpu@fd4b0000";
                lpd_dma_chan1 = "/axi/dma-controller@ffa80000";
                lpd_dma_chan2 = "/axi/dma-controller@ffa90000";
                lpd_dma_chan3 = "/axi/dma-controller@ffaa0000";
                lpd_dma_chan4 = "/axi/dma-controller@ffab0000";
                lpd_dma_chan5 = "/axi/dma-controller@ffac0000";
                lpd_dma_chan6 = "/axi/dma-controller@ffad0000";
                lpd_dma_chan7 = "/axi/dma-controller@ffae0000";
                lpd_dma_chan8 = "/axi/dma-controller@ffaf0000";
                mc = "/axi/memory-controller@fd070000";
                gem3 = "/axi/ethernet@ff0e0000";
                gpio = "/axi/gpio@ff0a0000";
                i2c0 = "/axi/i2c@ff020000";
                i2c1 = "/axi/i2c@ff030000";
                ocm = "/axi/memory-controller@ff960000";
                perf_monitor_ocm = "/axi/perf-monitor@ffa00000";
                perf_monitor_ddr = "/axi/perf-monitor@fd0b0000";
                perf_monitor_cci = "/axi/perf-monitor@fd490000";
                perf_monitor_lpd = "/axi/perf-monitor@ffa10000";
                qspi = "/axi/spi@ff0f0000";
                psgtr = "/axi/phy@fd400000";
                rtc = "/axi/rtc@ffa60000";
                sdhci1 = "/axi/mmc@ff170000";
                smmu = "/axi/iommu@fd800000";
                uart0 = "/axi/serial@ff000000";
                uart1 = "/axi/serial@ff010000";
                xilinx_ams = "/axi/ams@ffa50000";
                ams_ps = "/axi/ams@ffa50000/ams-ps@0";
                ams_pl = "/axi/ams@ffa50000/ams-pl@400";
                coresight_0 = "/axi/coresight@fe800000";
                csudma_0 = "/axi/dma@ffc80000";
                ipi0 = "/axi/ipi@ff300000";
                psu_ipi_0_0 = "/axi/ipi@ff300000/child@0";
                psu_ipi_0_1 = "/axi/ipi@ff300000/child@1";
                psu_ipi_0_2 = "/axi/ipi@ff300000/child@2";
                psu_ipi_0_3 = "/axi/ipi@ff300000/child@3";
                psu_ipi_0_4 = "/axi/ipi@ff300000/child@4";
                psu_ipi_0_5 = "/axi/ipi@ff300000/child@5";
                psu_ipi_0_6 = "/axi/ipi@ff300000/child@6";
                psu_r5_tcm_ram_global = "/axi/psu_r5_tcm_ram@ffe00000";
                psu_r5_tcm_ram_0 = "/axi/psu_r5_tcm_ram@0";
                psu_r5_1_btcm = "/axi/psu_r5_1_btcm@20000";
                psu_r5_1_btcm_global = "/axi/psu_r5_1_btcm_global@ffeb0000";
                psu_r5_1_atcm = "/axi/psu_r5_1_atcm@0";
                psu_r5_1_atcm_global = "/axi/psu_r5_1_atcm_global@ffe90000";
                psu_r5_0_btcm_lockstep = "/axi/psu_r5_0_btcm_lockstep@ffe30000";
                psu_r5_0_btcm = "/axi/psu_r5_0_btcm@20000";
                psu_r5_0_btcm_global = "/axi/psu_r5_0_btcm_global@ffe20000";
                psu_r5_0_atcm_lockstep = "/axi/psu_r5_0_atcm_lockstep@ffe10000";
                psu_r5_0_atcm = "/axi/psu_r5_0_atcm@0";
                psu_r5_0_atcm_global = "/axi/psu_r5_0_atcm_global@ffe00000";
                psu_pmu_global_0 = "/axi/psu_pmu_global_0@ffd80000";
                psu_mbistjtag = "/axi/psu_mbistjtag@ffcf0000";
                psu_rsa = "/axi/psu_rsa@ffce0000";
                psu_efuse = "/axi/psu_efuse@ffcc0000";
                psu_csu_0 = "/axi/psu_csu@ffca0000";
                psu_fpd_gpv = "/axi/psu_fpd_gpv@fd700000";
                psu_cci_gpv = "/axi/psu_cci_gpv@fd6e0000";
                psu_fpd_slcr_secure = "/axi/psu_fpd_slcr_secure@fd690000";
                psu_fpd_slcr = "/axi/psu_fpd_slcr@fd610000";
                psu_smmu_reg = "/axi/psu_smmu_reg@fd5f0000";
                psu_cci_reg = "/axi/psu_cci_reg@fd5e0000";
                psu_fpd_xmpu_cfg = "/axi/psu_fpd_xmpu_cfg@fd5d0000";
                psu_apu = "/axi/psu_apu@fd5c0000";
                psu_fpd_xmpu_sink = "/axi/psu_fpd_xmpu_sink@fd4f0000";
                psu_siou = "/axi/psu_siou@fd3d0000";
                psu_afi_5 = "/axi/psu_afi@fd3b0000";
                psu_afi_4 = "/axi/psu_afi@fd3a0000";
                psu_afi_3 = "/axi/psu_afi@fd390000";
                psu_afi_2 = "/axi/psu_afi@fd380000";
                psu_afi_1 = "/axi/psu_afi@fd370000";
                psu_afi_0 = "/axi/psu_afi@fd360000";
                psu_crf_apb = "/axi/psu_crf_apb@fd1a0000";
                psu_ddr_qos_ctrl = "/axi/psu_ddr_qos_ctrl@fd090000";
                psu_ddr_phy = "/axi/psu_ddr_phy@fd080000";
                psu_ddr_xmpu5_cfg = "/axi/psu_ddr_xmpu5_cfg@fd050000";
                psu_ddr_xmpu4_cfg = "/axi/psu_ddr_xmpu4_cfg@fd040000";
                psu_ddr_xmpu3_cfg = "/axi/psu_ddr_xmpu3_cfg@fd030000";
                psu_ddr_xmpu2_cfg = "/axi/psu_ddr_xmpu2_cfg@fd020000";
                psu_ddr_xmpu1_cfg = "/axi/psu_ddr_xmpu1_cfg@fd010000";
                psu_ddr_xmpu0_cfg = "/axi/psu_ddr_xmpu0_cfg@fd000000";
                psu_ocm_xmpu_cfg = "/axi/psu_ocm_xmpu_cfg@ffa70000";
                psu_lpd_xppu_sink = "/axi/psu_lpd_xppu_sink@ff9c0000";
                psu_afi_6 = "/axi/psu_afi@ff9b0000";
                psu_rpu = "/axi/psu_rpu@ff9a0000";
                psu_crl_apb = "/axi/psu_crl_apb@ff5e0000";
                psu_lpd_slcr_secure = "/axi/psu_lpd_slcr_secure@ff4b0000";
                psu_lpd_slcr = "/axi/psu_lpd_slcr@ff410000";
                psu_ctrl_ipi = "/axi/PERIPHERAL@ff380000";
                psu_message_buffers = "/axi/PERIPHERAL@ff990000";
                psu_iou_scntrs = "/axi/psu_iou_scntrs@ff260000";
                psu_iou_scntr = "/axi/psu_iou_scntr@ff250000";
                psu_iousecure_slcr = "/axi/psu_iousecure_slcr@ff240000";
                psu_iouslcr_0 = "/axi/psu_iouslcr@ff180000";
                psu_qspi_linear_0 = "/axi/psu_qspi_linear@c0000000";
                amba_xppu = "/indirect-bus@1";
                lpd_xppu = "/indirect-bus@1/xppu@ff980000";
                binman = "/binman";
                pss_ref_clk = "/pss-ref-clk";
                video_clk = "/video-clk";
                pss_alt_ref_clk = "/pss-alt-ref-clk";
                gt_crx_ref_clk = "/gt-crx-ref-clk";
                aux_ref_clk = "/aux-ref-clk";
                amba_pl = "/amba_pl";
                misc_clk_0 = "/amba_pl/misc_clk_0";
                misc_clk_1 = "/amba_pl/misc_clk_1";
                axi_bram_ctrl_0 = "/amba_pl/axi_bram_ctrl_0@a0000000";
                axi_bram_ctrl_1 = "/amba_pl/axi_bram_ctrl_1@a0001000";
                axi_bram_ctrl_2 = "/amba_pl/axi_bram_ctrl_2@a0002000";
                axi_bram_ctrl_3 = "/amba_pl/axi_bram_ctrl_3@a0003000";
                iodelay_if_0 = "/amba_pl/iodelay_if@b0000000";
                iodelay_if_0_dqs = "/amba_pl/iodelay_if@b0010000";
                nvme_ctrl_0 = "/amba_pl/nvme_ctrl@b0020000";
                t4nfc_hlper_0 = "/amba_pl/t4nfc_hlper@a0010000";
                t4nfc_hlper_1 = "/amba_pl/t4nfc_hlper@a0020000";
                t4nfc_hlper_2 = "/amba_pl/t4nfc_hlper@a0030000";
                t4nfc_hlper_3 = "/amba_pl/t4nfc_hlper@a0040000";
                axi_bram_ctrl_0_memory = "/memory@a0000000";
                axi_bram_ctrl_1_memory = "/memory@a0001000";
                axi_bram_ctrl_2_memory = "/memory@a0002000";
                axi_bram_ctrl_3_memory = "/memory@a0003000";
                psu_ocm_ram_0_memory = "/memory@FFFC0000";
                psu_ddr_0_memory = "/memory@0";
                psu_qspi_linear_0_memory = "/memory@c0000000";
                gic = "/axi/interrupt-controller@f9010000";
        };
};
